AUTOSAR XML (schema 4-2-2)
package /KPIT/ARPackage
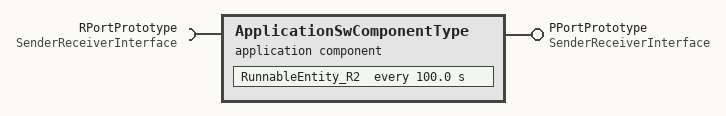
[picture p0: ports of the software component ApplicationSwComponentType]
  application sw component type ApplicationSwComponentType
    provide port PPortPrototype: provided-interface=SenderReceiverInterface
    require port RPortPrototype: required-interface=SenderReceiverInterface
    behavior SwcInternalBehavior_APSW_01: handle-termination-and-restart=NO-SUPPORT
      timing event TimingEvent_2: start-on-event=RunnableEntity_R2, period=100.0
      data received event DataReceivedEvent_APSW_01: start-on-event=RunnableEntity_R1
      35 x timing event:
        TimingEvent_1: start-on-event=RunnableEntity_R1, period=100.0
        TimingEvent_3: start-on-event=RunnableEntity_R3, period=200.0
        TimingEvent_4: start-on-event=RunnableEntity_R4, period=100.0
        TimingEvent_5: start-on-event=RunnableEntity_R5, period=100.0
        TimingEvent_18: start-on-event=RunnableEntity_R18, period=200.0
        TimingEvent_6: start-on-event=RunnableEntity_R6, period=200.0
        TimingEvent_7: start-on-event=RunnableEntity_R7, period=100.0
        TimingEvent_8: start-on-event=RunnableEntity_R8, period=100.0
        TimingEvent_9: start-on-event=RunnableEntity_R9, period=200.0
        TimingEvent_10: start-on-event=RunnableEntity_R10, period=100.0
        TimingEvent_11: start-on-event=RunnableEntity_R11, period=100.0
        TimingEvent_12: start-on-event=RunnableEntity_R12, period=200.0
        TimingEvent_13: start-on-event=RunnableEntity_R13, period=100.0
        TimingEvent_14: start-on-event=RunnableEntity_R14, period=100.0
        TimingEvent_15: start-on-event=RunnableEntity_R15, period=200.0
        TimingEvent_16: start-on-event=RunnableEntity_R16, period=100.0
        TimingEvent_17: start-on-event=RunnableEntity_R17, period=100.0
        TimingEvent_19: start-on-event=RunnableEntity_R1, period=100.0
        TimingEvent_20: start-on-event=RunnableEntity_R2, period=100.0
        TimingEvent_21: start-on-event=RunnableEntity_R3, period=200.0
        TimingEvent_22: start-on-event=RunnableEntity_R4, period=100.0
        TimingEvent_23: start-on-event=RunnableEntity_R5, period=100.0
        TimingEvent_24: start-on-event=RunnableEntity_R6, period=200.0
        TimingEvent_25: start-on-event=RunnableEntity_R7, period=100.0
        TimingEvent_26: start-on-event=RunnableEntity_R8, period=100.0
        TimingEvent_27: start-on-event=RunnableEntity_R9, period=200.0
        TimingEvent_28: start-on-event=RunnableEntity_R10, period=100.0
        TimingEvent_29: start-on-event=RunnableEntity_R11, period=100.0
        TimingEvent_30: start-on-event=RunnableEntity_R12, period=200.0
        TimingEvent_31: start-on-event=RunnableEntity_R13, period=100.0
        TimingEvent_32: start-on-event=RunnableEntity_R14, period=100.0
        TimingEvent_33: start-on-event=RunnableEntity_R15, period=200.0
        TimingEvent_34: start-on-event=RunnableEntity_R16, period=100.0
        TimingEvent_35: start-on-event=RunnableEntity_R17, period=100.0
        TimingEvent_36: start-on-event=RunnableEntity_R18, period=200.0
      36 x init event:
        InitEvent_I{1..18}: start-on-event=RunnableEntity_R{1..18}
        InitEvent_I19: start-on-event=RunnableEntity_R1
        InitEvent_I20: start-on-event=RunnableEntity_R2
        InitEvent_I21: start-on-event=RunnableEntity_R3
        InitEvent_I22: start-on-event=RunnableEntity_R4
        InitEvent_I23: start-on-event=RunnableEntity_R5
        InitEvent_I24: start-on-event=RunnableEntity_R6
        InitEvent_I25: start-on-event=RunnableEntity_R7
        InitEvent_I26: start-on-event=RunnableEntity_R8
        InitEvent_I27: start-on-event=RunnableEntity_R9
        InitEvent_I28: start-on-event=RunnableEntity_R10
        InitEvent_I29: start-on-event=RunnableEntity_R11
        InitEvent_I30: start-on-event=RunnableEntity_R12
        InitEvent_I31: start-on-event=RunnableEntity_R13
        InitEvent_I32: start-on-event=RunnableEntity_R14
        InitEvent_I33: start-on-event=RunnableEntity_R15
        InitEvent_I34: start-on-event=RunnableEntity_R16
        InitEvent_I35: start-on-event=RunnableEntity_R17
        InitEvent_I36: start-on-event=RunnableEntity_R18
      18 x runnable:
        RunnableEntity_R{1..14}
        RunnableEntity_R15: reentrancy-level=MULTICORE-REENTRANT
        RunnableEntity_R{16..18}
  sender receiver interface SenderReceiverInterface
    data VariableDataPrototype: type={Implementation_Data_type}
  module config Rte_0: definition=Rte, ecuc-def-edition=4.2.2, implementation-config-variant=VARIANT-PRE-COMPILE, module-description=Rte_Impl
    RteBswGeneral_0 (RteBswGeneral): RteSchMVersionInfoApi=true, RteUseComShadowSignalApi=false
    RteGeneration_0 (RteGeneration):
      RteBypassSupport = NONE
      RteCalibrationSupport = NONE
      RteCodeVendorId = 1
      RteDevErrorDetect = false
      RteDevErrorDetectUninit = false
      RteGenerationMode = COMPATIBILITY_MODE
      RteInExclusiveAreaCheckEnabled = true
      RteIocInteractionReturnValue = RTE_IOC
      RteMeasurementSupport = false
      RteOptimizationMode = RUNTIME
      RteValueRangeCheckEnabled = false
      RteVfbTraceEnabled = false
    RteInitializationBehavior_0 (RteInitializationBehavior): RteInitializationStrategy=RTE_INITIALIZATION_STRATEGY_AT_DATA_DECLARATION, RteSectionInitializationPolicy=1
    RteOsInteraction_0 (RteOsInteraction)
    72 x RteSwComponentInstance:
      RteSwComponentInstance_0
        RteEventToTaskMapping_0 (RteEventToTaskMapping):
          RteImmediateRestart = false
          RtePositionInTask = 1
          RteOsSchedulePoint = CONDITIONAL
          RteActivationOffset = 0
          RteEventRef = TimingEvent_1
          RteMappedToTaskRef = OsTask_0
          RteUsedOsAlarmRef = OsAlarm_0
          RteUsedOsEventRef = (unset)
      RteSwComponentInstance_1
        RteEventToTaskMapping_1 (RteEventToTaskMapping):
          RteImmediateRestart = false
          RteActivationOffset = 0
          RteOsSchedulePoint = CONDITIONAL
          RtePositionInTask = 2
          RteEventRef = TimingEvent_2
          RteMappedToTaskRef = OsTask_0
          RteUsedOsAlarmRef = OsAlarm_0
          RteUsedOsEventRef = (unset)
        RteInternalTriggerConfig_0 (RteInternalTriggerConfig): RteTriggerSourceQueueLength=0, RteSwcTriggerSourceRef=(unset)
      RteSwComponentInstance_2
        RteEventToTaskMapping_2 (RteEventToTaskMapping):
          RteImmediateRestart = false
          RteActivationOffset = 0
          RtePositionInTask = 3
          RteOsSchedulePoint = CONDITIONAL
          RteEventRef = TimingEvent_3
          RteMappedToTaskRef = OsTask_0
          RteUsedOsAlarmRef = OsAlarm_0
          RteUsedOsEventRef = (unset)
      RteSwComponentInstance_3
        RteEventToTaskMapping_3 (RteEventToTaskMapping):
          RteImmediateRestart = false
          RteActivationOffset = 0
          RteOsSchedulePoint = CONDITIONAL
          RtePositionInTask = 1
          RteEventRef = TimingEvent_4
          RteMappedToTaskRef = OsTask_1
          RteUsedOsAlarmRef = OsAlarm_1
          RteUsedOsEventRef = (unset)
      RteSwComponentInstance_4
        RteEventToTaskMapping_4 (RteEventToTaskMapping):
          RteImmediateRestart = false
          RteActivationOffset = 0
          RteOsSchedulePoint = CONDITIONAL
          RtePositionInTask = 2
          RteEventRef = TimingEvent_5
          RteUsedOsAlarmRef = OsAlarm_1
          RteUsedOsEventRef = (unset)
          RteMappedToTaskRef = OsTask_1
      RteSwComponentInstance_5
        RteEventToTaskMapping_5 (RteEventToTaskMapping):
          RteImmediateRestart = false
          RteActivationOffset = 0
          RtePositionInTask = 3
          RteOsSchedulePoint = CONDITIONAL
          RteEventRef = TimingEvent_6
          RteMappedToTaskRef = OsTask_1
          RteUsedOsAlarmRef = OsAlarm_1
      RteSwComponentInstance_6
        RteEventToTaskMapping_6 (RteEventToTaskMapping):
          RteImmediateRestart = false
          RteActivationOffset = 0
          RteOsSchedulePoint = CONDITIONAL
          RtePositionInTask = 1
          RteEventRef = TimingEvent_7
          RteUsedOsAlarmRef = OsAlarm_2
          RteMappedToTaskRef = OsTask_2
      RteSwComponentInstance_7
        RteEventToTaskMapping_7 (RteEventToTaskMapping):
          RteImmediateRestart = false
          RteActivationOffset = 0
          RteOsSchedulePoint = CONDITIONAL
          RtePositionInTask = 2
          RteEventRef = TimingEvent_8
          RteUsedOsAlarmRef = OsAlarm_2
          RteMappedToTaskRef = OsTask_2
      RteSwComponentInstance_8
        RteEventToTaskMapping_8 (RteEventToTaskMapping):
          RteImmediateRestart = false
          RteActivationOffset = 0
          RtePositionInTask = 3
          RteOsSchedulePoint = CONDITIONAL
          RteEventRef = TimingEvent_9
          RteUsedOsAlarmRef = OsAlarm_2
          RteMappedToTaskRef = OsTask_2
      RteSwComponentInstance_9
        RteEventToTaskMapping_9 (RteEventToTaskMapping):
          RteImmediateRestart = false
          RtePositionInTask = 1
          RteOsSchedulePoint = CONDITIONAL
          RteActivationOffset = 0
          RteEventRef = TimingEvent_10
          RteMappedToTaskRef = OsTask_3
          RteUsedOsAlarmRef = OsAlarm_3
      RteSwComponentInstance_10
        RteEventToTaskMapping_10 (RteEventToTaskMapping):
          RteImmediateRestart = false
          RteActivationOffset = 0
          RtePositionInTask = 2
          RteOsSchedulePoint = CONDITIONAL
          RteEventRef = TimingEvent_11
          RteMappedToTaskRef = OsTask_3
          RteUsedOsAlarmRef = OsAlarm_3
      RteSwComponentInstance_11
        RteEventToTaskMapping_11 (RteEventToTaskMapping):
          RteImmediateRestart = false
          RteActivationOffset = 0
          RtePositionInTask = 3
          RteOsSchedulePoint = CONDITIONAL
          RteEventRef = TimingEvent_12
          RteMappedToTaskRef = OsTask_3
          RteUsedOsAlarmRef = OsAlarm_3
      RteSwComponentInstance_12
        RteEventToTaskMapping_12 (RteEventToTaskMapping):
          RteImmediateRestart = false
          RteActivationOffset = 0
          RteOsSchedulePoint = CONDITIONAL
          RtePositionInTask = 1
          RteEventRef = TimingEvent_13
          RteMappedToTaskRef = OsTask_4
          RteUsedOsAlarmRef = OsAlarm_4
      RteSwComponentInstance_13
        RteEventToTaskMapping_13 (RteEventToTaskMapping):
          RteImmediateRestart = false
          RteOsSchedulePoint = CONDITIONAL
          RtePositionInTask = 2
          RteActivationOffset = 0
          RteEventRef = TimingEvent_14
          RteMappedToTaskRef = OsTask_4
          RteUsedOsAlarmRef = OsAlarm_4
      RteSwComponentInstance_14
        RteEventToTaskMapping_14 (RteEventToTaskMapping):
          RteImmediateRestart = false
          RteActivationOffset = 0
          RteOsSchedulePoint = CONDITIONAL
          RtePositionInTask = 3
          RteEventRef = TimingEvent_15
          RteMappedToTaskRef = OsTask_4
          RteUsedOsAlarmRef = OsAlarm_4
      RteSwComponentInstance_15
        RteEventToTaskMapping_15 (RteEventToTaskMapping):
          RteImmediateRestart = false
          RteActivationOffset = 0
          RtePositionInTask = 1
          RteOsSchedulePoint = CONDITIONAL
          RteEventRef = TimingEvent_16
          RteMappedToTaskRef = OsTask_5
          RteUsedOsAlarmRef = OsAlarm_5
      RteSwComponentInstance_16
        RteEventToTaskMapping_16 (RteEventToTaskMapping):
          RteImmediateRestart = false
          RteActivationOffset = 0
          RteOsSchedulePoint = CONDITIONAL
          RtePositionInTask = 2
          RteEventRef = TimingEvent_17
          RteMappedToTaskRef = OsTask_5
          RteUsedOsAlarmRef = OsAlarm_5
      RteSwComponentInstance_17
        RteEventToTaskMapping_17 (RteEventToTaskMapping):
          RteImmediateRestart = false
          RteActivationOffset = 0
          RtePositionInTask = 3
          RteOsSchedulePoint = CONDITIONAL
          RteEventRef = TimingEvent_18
          RteMappedToTaskRef = OsTask_5
          RteUsedOsAlarmRef = OsAlarm_5
      RteSwComponentInstance_18
        RteEventToTaskMapping_18 (RteEventToTaskMapping):
          RteImmediateRestart = false
          RteActivationOffset = 0
          RtePositionInTask = 1
          RteOsSchedulePoint = CONDITIONAL
          RteEventRef = TimingEvent_19
          RteMappedToTaskRef = OsTask_6
          RteUsedOsAlarmRef = OsAlarm_6
      RteSwComponentInstance_19
        RteEventToTaskMapping_19 (RteEventToTaskMapping):
          RteImmediateRestart = false
          RteActivationOffset = 0
          RtePositionInTask = 2
          RteOsSchedulePoint = CONDITIONAL
          RteEventRef = TimingEvent_20
          RteMappedToTaskRef = OsTask_6
          RteUsedOsAlarmRef = OsAlarm_6
      RteSwComponentInstance_20
        RteEventToTaskMapping_20 (RteEventToTaskMapping):
          RteImmediateRestart = false
          RteActivationOffset = 0
          RteOsSchedulePoint = CONDITIONAL
          RtePositionInTask = 3
          RteEventRef = TimingEvent_21
          RteMappedToTaskRef = OsTask_6
          RteUsedOsAlarmRef = OsAlarm_6
      RteSwComponentInstance_21
        RteEventToTaskMapping_21 (RteEventToTaskMapping):
          RteImmediateRestart = false
          RteActivationOffset = 0
          RtePositionInTask = 1
          RteOsSchedulePoint = CONDITIONAL
          RteEventRef = TimingEvent_22
          RteMappedToTaskRef = OsTask_7
          RteUsedOsAlarmRef = OsAlarm_7
      RteSwComponentInstance_22
        RteEventToTaskMapping_22 (RteEventToTaskMapping):
          RteImmediateRestart = false
          RteActivationOffset = 0
          RtePositionInTask = 2
          RteOsSchedulePoint = CONDITIONAL
          RteEventRef = TimingEvent_23
          RteMappedToTaskRef = OsTask_7
          RteUsedOsAlarmRef = OsAlarm_7
      RteSwComponentInstance_23
        RteEventToTaskMapping_23 (RteEventToTaskMapping):
          RteImmediateRestart = false
          RteActivationOffset = 0
          RtePositionInTask = 3
          RteOsSchedulePoint = CONDITIONAL
          RteEventRef = TimingEvent_24
          RteMappedToTaskRef = OsTask_7
          RteUsedOsAlarmRef = OsAlarm_7
      RteSwComponentInstance_24
        RteEventToTaskMapping_24 (RteEventToTaskMapping):
          RteImmediateRestart = false
          RteActivationOffset = 0
          RteOsSchedulePoint = CONDITIONAL
          RtePositionInTask = 1
          RteEventRef = TimingEvent_25
          RteMappedToTaskRef = OsTask_8
          RteUsedOsAlarmRef = OsAlarm_8
      RteSwComponentInstance_25
        RteEventToTaskMapping_25 (RteEventToTaskMapping):
          RteImmediateRestart = false
          RteActivationOffset = 0
          RteOsSchedulePoint = CONDITIONAL
          RtePositionInTask = 2
          RteEventRef = TimingEvent_26
          RteMappedToTaskRef = OsTask_8
          RteUsedOsAlarmRef = OsAlarm_8
      RteSwComponentInstance_26
        RteEventToTaskMapping_26 (RteEventToTaskMapping):
          RteImmediateRestart = false
          RteActivationOffset = 0
          RtePositionInTask = 3
          RteOsSchedulePoint = CONDITIONAL
          RteEventRef = TimingEvent_27
          RteMappedToTaskRef = OsTask_8
          RteUsedOsAlarmRef = OsAlarm_8
      RteSwComponentInstance_27
        RteEventToTaskMapping_27 (RteEventToTaskMapping):
          RteImmediateRestart = false
          RteActivationOffset = 0
          RteOsSchedulePoint = CONDITIONAL
          RtePositionInTask = 1
          RteEventRef = TimingEvent_28
          RteMappedToTaskRef = OsTask_9
          RteUsedOsAlarmRef = OsAlarm_9
      RteSwComponentInstance_28
        RteEventToTaskMapping_28 (RteEventToTaskMapping):
          RteImmediateRestart = false
          RteActivationOffset = 0
          RteOsSchedulePoint = CONDITIONAL
          RtePositionInTask = 2
          RteEventRef = TimingEvent_29
          RteMappedToTaskRef = OsTask_9
          RteUsedOsAlarmRef = OsAlarm_9
      RteSwComponentInstance_29
        RteEventToTaskMapping_29 (RteEventToTaskMapping):
          RteImmediateRestart = false
          RteActivationOffset = 0
          RteOsSchedulePoint = CONDITIONAL
          RtePositionInTask = 3
          RteEventRef = TimingEvent_30
          RteMappedToTaskRef = OsTask_9
          RteUsedOsAlarmRef = OsAlarm_9
      RteSwComponentInstance_30
        RteEventToTaskMapping_30 (RteEventToTaskMapping):
          RteImmediateRestart = false
          RteActivationOffset = 0
          RteOsSchedulePoint = CONDITIONAL
          RtePositionInTask = 1
          RteEventRef = TimingEvent_31
          RteMappedToTaskRef = OsTask_10
          RteUsedOsAlarmRef = OsAlarm_10
      RteSwComponentInstance_31
        RteEventToTaskMapping_31 (RteEventToTaskMapping):
          RteImmediateRestart = false
          RteActivationOffset = 0
          RteOsSchedulePoint = CONDITIONAL
          RtePositionInTask = 2
          RteEventRef = TimingEvent_32
          RteMappedToTaskRef = OsTask_10
          RteUsedOsAlarmRef = OsAlarm_10
      RteSwComponentInstance_32
        RteEventToTaskMapping_32 (RteEventToTaskMapping):
          RteImmediateRestart = false
          RteActivationOffset = 0
          RtePositionInTask = 3
          RteOsSchedulePoint = CONDITIONAL
          RteEventRef = TimingEvent_33
          RteMappedToTaskRef = OsTask_10
          RteUsedOsAlarmRef = OsAlarm_10
      RteSwComponentInstance_33
        RteEventToTaskMapping_33 (RteEventToTaskMapping):
          RteImmediateRestart = false
          RteActivationOffset = 0
          RteOsSchedulePoint = CONDITIONAL
          RtePositionInTask = 1
          RteEventRef = TimingEvent_34
          RteMappedToTaskRef = OsTask_11
          RteUsedOsAlarmRef = OsAlarm_11
      RteSwComponentInstance_34
        RteEventToTaskMapping_34 (RteEventToTaskMapping):
          RteImmediateRestart = false
          RteActivationOffset = 0
          RteOsSchedulePoint = CONDITIONAL
          RtePositionInTask = 2
          RteEventRef = TimingEvent_35
          RteMappedToTaskRef = OsTask_11
          RteUsedOsAlarmRef = OsAlarm_11
      RteSwComponentInstance_35
        RteEventToTaskMapping_35 (RteEventToTaskMapping):
          RteImmediateRestart = false
          RteActivationOffset = 0
          RteOsSchedulePoint = CONDITIONAL
          RtePositionInTask = 3
          RteEventRef = TimingEvent_36
          RteMappedToTaskRef = OsTask_11
          RteUsedOsAlarmRef = OsAlarm_11
      RteSwComponentInstance_36
        RteEventToTaskMapping_0 (RteEventToTaskMapping):
          RteImmediateRestart = false
          RtePositionInTask = 1
          RteOsSchedulePoint = CONDITIONAL
          RteActivationOffset = 0
          RteEventRef = InitEvent_I1
          RteMappedToTaskRef = OsTask_12
          RteUsedOsAlarmRef = (unset)
          RteUsedOsEventRef = (unset)
      RteSwComponentInstance_37
        RteEventToTaskMapping_1 (RteEventToTaskMapping):
          RteImmediateRestart = false
          RteActivationOffset = 0
          RteOsSchedulePoint = CONDITIONAL
          RtePositionInTask = 2
          RteEventRef = InitEvent_I2
          RteMappedToTaskRef = OsTask_12
          RteUsedOsAlarmRef = (unset)
          RteUsedOsEventRef = (unset)
        RteInternalTriggerConfig_0 (RteInternalTriggerConfig): RteTriggerSourceQueueLength=0, RteSwcTriggerSourceRef=(unset)
      RteSwComponentInstance_38
        RteEventToTaskMapping_2 (RteEventToTaskMapping):
          RteImmediateRestart = false
          RteActivationOffset = 0
          RtePositionInTask = 3
          RteOsSchedulePoint = CONDITIONAL
          RteEventRef = InitEvent_I3
          RteMappedToTaskRef = OsTask_12
          RteUsedOsAlarmRef = (unset)
          RteUsedOsEventRef = (unset)
      RteSwComponentInstance_39
        RteEventToTaskMapping_3 (RteEventToTaskMapping):
          RteImmediateRestart = false
          RteActivationOffset = 0
          RteOsSchedulePoint = CONDITIONAL
          RtePositionInTask = 1
          RteEventRef = InitEvent_I4
          RteMappedToTaskRef = OsTask_13
          RteUsedOsAlarmRef = (unset)
          RteUsedOsEventRef = (unset)
      RteSwComponentInstance_40
        RteEventToTaskMapping_4 (RteEventToTaskMapping):
          RteImmediateRestart = false
          RteActivationOffset = 0
          RteOsSchedulePoint = CONDITIONAL
          RtePositionInTask = 2
          RteEventRef = InitEvent_I5
          RteUsedOsAlarmRef = (unset)
          RteUsedOsEventRef = (unset)
          RteMappedToTaskRef = OsTask_13
      RteSwComponentInstance_41
        RteEventToTaskMapping_5 (RteEventToTaskMapping):
          RteImmediateRestart = false
          RteActivationOffset = 0
          RtePositionInTask = 3
          RteOsSchedulePoint = CONDITIONAL
          RteEventRef = InitEvent_I6
          RteMappedToTaskRef = OsTask_13
          RteUsedOsAlarmRef = (unset)
      RteSwComponentInstance_42
        RteEventToTaskMapping_6 (RteEventToTaskMapping):
          RteImmediateRestart = false
          RteActivationOffset = 0
          RteOsSchedulePoint = CONDITIONAL
          RtePositionInTask = 1
          RteEventRef = InitEvent_I7
          RteUsedOsAlarmRef = (unset)
          RteMappedToTaskRef = OsTask_14
      RteSwComponentInstance_43
        RteEventToTaskMapping_7 (RteEventToTaskMapping):
          RteImmediateRestart = false
          RteActivationOffset = 0
          RteOsSchedulePoint = CONDITIONAL
          RtePositionInTask = 2
          RteEventRef = InitEvent_I8
          RteUsedOsAlarmRef = (unset)
          RteMappedToTaskRef = OsTask_14
      RteSwComponentInstance_44
        RteEventToTaskMapping_8 (RteEventToTaskMapping):
          RteImmediateRestart = false
          RteActivationOffset = 0
          RtePositionInTask = 3
          RteOsSchedulePoint = CONDITIONAL
          RteEventRef = InitEvent_I9
          RteUsedOsAlarmRef = (unset)
          RteMappedToTaskRef = OsTask_14
      RteSwComponentInstance_45
        RteEventToTaskMapping_9 (RteEventToTaskMapping):
          RteImmediateRestart = false
          RtePositionInTask = 1
          RteOsSchedulePoint = CONDITIONAL
          RteActivationOffset = 0
          RteEventRef = InitEvent_I10
          RteMappedToTaskRef = OsTask_15
          RteUsedOsAlarmRef = (unset)
      RteSwComponentInstance_46
        RteEventToTaskMapping_10 (RteEventToTaskMapping):
          RteImmediateRestart = false
          RteActivationOffset = 0
          RtePositionInTask = 2
          RteOsSchedulePoint = CONDITIONAL
          RteEventRef = InitEvent_I11
          RteMappedToTaskRef = OsTask_15
          RteUsedOsAlarmRef = (unset)
      RteSwComponentInstance_47
        RteEventToTaskMapping_11 (RteEventToTaskMapping):
          RteImmediateRestart = false
          RteActivationOffset = 0
          RtePositionInTask = 3
          RteOsSchedulePoint = CONDITIONAL
          RteEventRef = InitEvent_I12
          RteMappedToTaskRef = OsTask_15
          RteUsedOsAlarmRef = (unset)
      RteSwComponentInstance_48
        RteEventToTaskMapping_12 (RteEventToTaskMapping):
          RteImmediateRestart = false
          RteActivationOffset = 0
          RteOsSchedulePoint = CONDITIONAL
          RtePositionInTask = 1
          RteEventRef = InitEvent_I13
          RteMappedToTaskRef = OsTask_16
          RteUsedOsAlarmRef = (unset)
      RteSwComponentInstance_49
        RteEventToTaskMapping_13 (RteEventToTaskMapping):
          RteImmediateRestart = false
          RteOsSchedulePoint = CONDITIONAL
          RtePositionInTask = 2
          RteActivationOffset = 0
          RteEventRef = InitEvent_I14
          RteMappedToTaskRef = OsTask_16
          RteUsedOsAlarmRef = (unset)
      RteSwComponentInstance_50
        RteEventToTaskMapping_14 (RteEventToTaskMapping):
          RteImmediateRestart = false
          RteActivationOffset = 0
          RteOsSchedulePoint = CONDITIONAL
          RtePositionInTask = 3
          RteEventRef = InitEvent_I15
          RteMappedToTaskRef = OsTask_16
          RteUsedOsAlarmRef = (unset)
      RteSwComponentInstance_51
        RteEventToTaskMapping_15 (RteEventToTaskMapping):
          RteImmediateRestart = false
          RteActivationOffset = 0
          RtePositionInTask = 1
          RteOsSchedulePoint = CONDITIONAL
          RteEventRef = InitEvent_I16
          RteMappedToTaskRef = OsTask_17
          RteUsedOsAlarmRef = (unset)
      RteSwComponentInstance_52
        RteEventToTaskMapping_16 (RteEventToTaskMapping):
          RteImmediateRestart = false
          RteActivationOffset = 0
          RteOsSchedulePoint = CONDITIONAL
          RtePositionInTask = 2
          RteEventRef = InitEvent_I17
          RteMappedToTaskRef = OsTask_17
          RteUsedOsAlarmRef = (unset)
      RteSwComponentInstance_53
        RteEventToTaskMapping_17 (RteEventToTaskMapping):
          RteImmediateRestart = false
          RteActivationOffset = 0
          RtePositionInTask = 3
          RteOsSchedulePoint = CONDITIONAL
          RteEventRef = InitEvent_I18
          RteMappedToTaskRef = OsTask_17
          RteUsedOsAlarmRef = (unset)
      RteSwComponentInstance_54
        RteEventToTaskMapping_18 (RteEventToTaskMapping):
          RteImmediateRestart = false
          RteActivationOffset = 0
          RtePositionInTask = 1
          RteOsSchedulePoint = CONDITIONAL
          RteEventRef = InitEvent_I19
          RteMappedToTaskRef = OsTask_18
          RteUsedOsAlarmRef = (unset)
      RteSwComponentInstance_55
        RteEventToTaskMapping_19 (RteEventToTaskMapping):
          RteImmediateRestart = false
          RteActivationOffset = 0
          RtePositionInTask = 2
          RteOsSchedulePoint = CONDITIONAL
          RteEventRef = InitEvent_I20
          RteMappedToTaskRef = OsTask_18
          RteUsedOsAlarmRef = (unset)
      RteSwComponentInstance_56
        RteEventToTaskMapping_20 (RteEventToTaskMapping):
          RteImmediateRestart = false
          RteActivationOffset = 0
          RteOsSchedulePoint = CONDITIONAL
          RtePositionInTask = 3
          RteEventRef = InitEvent_I21
          RteMappedToTaskRef = OsTask_18
          RteUsedOsAlarmRef = (unset)
      RteSwComponentInstance_57
        RteEventToTaskMapping_21 (RteEventToTaskMapping):
          RteImmediateRestart = false
          RteActivationOffset = 0
          RtePositionInTask = 1
          RteOsSchedulePoint = CONDITIONAL
          RteEventRef = InitEvent_I22
          RteMappedToTaskRef = OsTask_19
          RteUsedOsAlarmRef = (unset)
      RteSwComponentInstance_58
        RteEventToTaskMapping_22 (RteEventToTaskMapping):
          RteImmediateRestart = false
          RteActivationOffset = 0
          RtePositionInTask = 2
          RteOsSchedulePoint = CONDITIONAL
          RteEventRef = InitEvent_I23
          RteMappedToTaskRef = OsTask_19
          RteUsedOsAlarmRef = (unset)
      RteSwComponentInstance_59
        RteEventToTaskMapping_23 (RteEventToTaskMapping):
          RteImmediateRestart = false
          RteActivationOffset = 0
          RtePositionInTask = 3
          RteOsSchedulePoint = CONDITIONAL
          RteEventRef = InitEvent_I24
          RteMappedToTaskRef = OsTask_19
          RteUsedOsAlarmRef = (unset)
        RteExclusiveAreaImplementation_0 (RteExclusiveAreaImplementation): RteExclusiveAreaImplMechanism=, RteExclusiveAreaRef=(unset)
      RteSwComponentInstance_60
        RteEventToTaskMapping_24 (RteEventToTaskMapping):
          RteImmediateRestart = false
          RteActivationOffset = 0
          RteOsSchedulePoint = CONDITIONAL
          RtePositionInTask = 1
          RteEventRef = InitEvent_I25
          RteMappedToTaskRef = OsTask_20
          RteUsedOsAlarmRef = (unset)
      RteSwComponentInstance_61
        RteEventToTaskMapping_25 (RteEventToTaskMapping):
          RteImmediateRestart = false
          RteActivationOffset = 0
          RteOsSchedulePoint = CONDITIONAL
          RtePositionInTask = 2
          RteEventRef = InitEvent_I26
          RteMappedToTaskRef = OsTask_20
          RteUsedOsAlarmRef = (unset)
      RteSwComponentInstance_62
        RteEventToTaskMapping_26 (RteEventToTaskMapping):
          RteImmediateRestart = false
          RteActivationOffset = 0
          RtePositionInTask = 3
          RteOsSchedulePoint = CONDITIONAL
          RteEventRef = InitEvent_I27
          RteMappedToTaskRef = OsTask_20
          RteUsedOsAlarmRef = (unset)
      RteSwComponentInstance_63
        RteEventToTaskMapping_27 (RteEventToTaskMapping):
          RteImmediateRestart = false
          RteActivationOffset = 0
          RteOsSchedulePoint = CONDITIONAL
          RtePositionInTask = 1
          RteEventRef = InitEvent_I28
          RteMappedToTaskRef = OsTask_21
          RteUsedOsAlarmRef = (unset)
      RteSwComponentInstance_64
        RteEventToTaskMapping_28 (RteEventToTaskMapping):
          RteImmediateRestart = false
          RteActivationOffset = 0
          RteOsSchedulePoint = CONDITIONAL
          RtePositionInTask = 2
          RteEventRef = InitEvent_I29
          RteMappedToTaskRef = OsTask_21
          RteUsedOsAlarmRef = (unset)
      RteSwComponentInstance_65
        RteEventToTaskMapping_29 (RteEventToTaskMapping):
          RteImmediateRestart = false
          RteActivationOffset = 0
          RteOsSchedulePoint = CONDITIONAL
          RtePositionInTask = 3
          RteEventRef = InitEvent_I30
          RteMappedToTaskRef = OsTask_21
          RteUsedOsAlarmRef = (unset)
      RteSwComponentInstance_66
        RteEventToTaskMapping_30 (RteEventToTaskMapping):
          RteImmediateRestart = false
          RteActivationOffset = 0
          RteOsSchedulePoint = CONDITIONAL
          RtePositionInTask = 1
          RteEventRef = InitEvent_I31
          RteMappedToTaskRef = OsTask_22
          RteUsedOsAlarmRef = (unset)
      RteSwComponentInstance_67
        RteEventToTaskMapping_31 (RteEventToTaskMapping):
          RteImmediateRestart = false
          RteActivationOffset = 0
          RteOsSchedulePoint = CONDITIONAL
          RtePositionInTask = 2
          RteEventRef = InitEvent_I32
          RteMappedToTaskRef = OsTask_22
          RteUsedOsAlarmRef = (unset)
      RteSwComponentInstance_68
        RteEventToTaskMapping_32 (RteEventToTaskMapping):
          RteImmediateRestart = false
          RteActivationOffset = 0
          RtePositionInTask = 3
          RteOsSchedulePoint = CONDITIONAL
          RteEventRef = InitEvent_I33
          RteMappedToTaskRef = OsTask_22
          RteUsedOsAlarmRef = (unset)
      RteSwComponentInstance_69
        RteEventToTaskMapping_33 (RteEventToTaskMapping):
          RteImmediateRestart = false
          RteActivationOffset = 0
          RteOsSchedulePoint = CONDITIONAL
          RtePositionInTask = 1
          RteEventRef = InitEvent_I34
          RteMappedToTaskRef = OsTask_23
          RteUsedOsAlarmRef = (unset)
      RteSwComponentInstance_70
        RteEventToTaskMapping_34 (RteEventToTaskMapping):
          RteImmediateRestart = false
          RteActivationOffset = 0
          RteOsSchedulePoint = CONDITIONAL
          RtePositionInTask = 2
          RteEventRef = InitEvent_I35
          RteMappedToTaskRef = OsTask_23
          RteUsedOsAlarmRef = (unset)
      RteSwComponentInstance_71
        RteEventToTaskMapping_35 (RteEventToTaskMapping):
          RteImmediateRestart = false
          RteActivationOffset = 0
          RteOsSchedulePoint = CONDITIONAL
          RtePositionInTask = 3
          RteEventRef = InitEvent_I36
          RteMappedToTaskRef = OsTask_23
          RteUsedOsAlarmRef = (unset)
  module config Os_0: definition=Os, ecuc-def-edition=1.1.0, implementation-config-variant=VARIANT-PRE-COMPILE, module-description=BswImplementation_Os
    OsAppMode_1 (OsAppMode)
    OsOS_0 (OsOS):
      OsIdleTaskStackSize = 600
      OsProcessor = MPC5748G
      OsStackMonitoring = false
      OsStatus = STANDARD
      OsUseGetServiceId = false
      OsUseParameterAccess = false
      OsUseResScheduler = true
      OsHooks_0 (OsHooks): OsErrorHook=false, OsPostTaskHook=false, OsPreTaskHook=false, OsShutdownHook=false, OsStartupHook=false
    6 x OsTask, all with OsTaskStackSize=800:
      OsTask_0: OsTaskActivation=2, OsTaskPriority=1, OsTaskSchedule=FULL
        OsTaskTimingProtection_0 (OsTaskTimingProtection)
        OsTaskAutostart_0 (OsTaskAutostart): OsTaskAppModeRef=OsAppMode_1
      OsTask_1: OsTaskActivation=1, OsTaskPriority=2, OsTaskSchedule=NON
        OsTaskAutostart_0 (OsTaskAutostart): OsTaskAppModeRef=OsAppMode_1
      OsTask_2: OsTaskActivation=1, OsTaskPriority=3, OsTaskSchedule=FULL
        OsTaskAutostart_0 (OsTaskAutostart): OsTaskAppModeRef=OsAppMode_1
        OsTaskTimingProtection_0 (OsTaskTimingProtection)
      OsTask_3: OsTaskActivation=2, OsTaskPriority=4, OsTaskSchedule=NON
        OsTaskTimingProtection_0 (OsTaskTimingProtection): OsTaskTimeFrame=0.0000002
      OsTask_4: OsTaskActivation=1, OsTaskPriority=5, OsTaskSchedule=FULL
        OsTaskTimingProtection_0 (OsTaskTimingProtection)
      OsTask_5: OsTaskActivation=2, OsTaskPriority=6, OsTaskSchedule=FULL
        OsTaskTimingProtection_0 (OsTaskTimingProtection): OsTaskTimeFrame=0.0000005
    4 x OsAlarm:
      OsAlarm_1: OsAlarmCounterRef=OsCounter_1
        OsAlarmAction_1 (OsAlarmAction)
          OsAlarmActivateTask_1 (OsAlarmActivateTask): OsAlarmActivateTaskRef=OsTask_1
        OsAlarmAutostart_1 (OsAlarmAutostart): OsAlarmAlarmTime=1, OsAlarmAutostartType=RELATIVE, OsAlarmCycleTime=0, OsAlarmAppModeRef=OsAppMode_1
      OsAlarm_2: OsAlarmCounterRef=OsCounter_0
        OsAlarmAction_2 (OsAlarmAction)
          OsAlarmActivateTask_2 (OsAlarmActivateTask): OsAlarmActivateTaskRef=OsTask_2
        OsAlarmAutostart_2 (OsAlarmAutostart): OsAlarmAlarmTime=1, OsAlarmAutostartType=RELATIVE, OsAlarmCycleTime=0, OsAlarmAppModeRef=OsAppMode_1
      OsAlarm_3: OsAlarmCounterRef=OsCounter_1
        OsAlarmAction_3 (OsAlarmAction)
          OsAlarmActivateTask_3 (OsAlarmActivateTask): OsAlarmActivateTaskRef=OsTask_3
        OsAlarmAutostart_0 (OsAlarmAutostart): OsAlarmAlarmTime=1, OsAlarmAutostartType=RELATIVE, OsAlarmCycleTime=0, OsAlarmAppModeRef=OsAppMode_1
      OsAlarm_4: OsAlarmCounterRef=OsCounter_0
        OsAlarmAction_4 (OsAlarmAction)
          OsAlarmActivateTask_4 (OsAlarmActivateTask): OsAlarmActivateTaskRef=OsTask_4
        OsAlarmAutostart_0 (OsAlarmAutostart): OsAlarmAlarmTime=1, OsAlarmAutostartType=RELATIVE, OsAlarmCycleTime=0, OsAlarmAppModeRef=OsAppMode_1
    4 x OsCounter, all with OsCounterMaxAllowedValue=1, OsCounterMinCycle=1, OsCounterTicksPerBase=1, OsCounterType=HARDWARE, OsSecondsPerTick=0.0000002:
      OsCounter_0: OsDrivingInterrupt=
        OsDriver_0 (OsDriver)
      OsCounter_1
      OsCounter_2
        OsTimeConstant_0 (OsTimeConstant): OsTimeValue=0, OsConstName=(unset)
      OsCounter_3
    OsAlarm_0 (OsAlarm): OsAlarmCounterRef=OsCounter_0
      OsAlarmAction_0 (OsAlarmAction)
        OsAlarmActivateTask_0 (OsAlarmActivateTask): OsAlarmActivateTaskRef=OsTask_0
      OsAlarmAutostart_0 (OsAlarmAutostart): OsAlarmAlarmTime=1, OsAlarmAutostartType=RELATIVE, OsAlarmCycleTime=0, OsAlarmAppModeRef=OsAppMode_1
    OsApplication_0 (OsApplication):
      OsTrusted = false
      OsTrustedApplicationDelayTimingViolationCall = true
      OsTrustedApplicationWithProtection = false
      OsPeripheralAcess = 
      OsAppAlarmRef = OsAlarm_0
      OsAppCounterRef = OsCounter_0
      OsAppTaskRef = OsTask_0
      OsApplicationCoreRef = EcucCoreDefinition_0
      OsAppEcucPartitionRef = Partition0
      OsAppAlarmRef = OsAlarm_{1..5}
      OsAppCounterRef = OsCounter_1
      OsAppIsrRef = OsIsr_0
      OsAppIsrRef = OsIsr_1
      OsAppTaskRef = OsTask_{1..5}
      OsAppIsrRef = OsIsr_{2..4}
      OsAppTaskRef = OsTask_{12..17}
      OsApplicationHooks_0 (OsApplicationHooks): OsAppErrorHook=false, OsAppShutdownHook=false, OsAppStartupHook=false
    OsApplication_1 (OsApplication):
      OsTrusted = false
      OsTrustedApplicationDelayTimingViolationCall = true
      OsTrustedApplicationWithProtection = false
      OsAppAlarmRef = OsAlarm_6
      OsAppCounterRef = OsCounter_2
      OsAppTaskRef = OsTask_6
      OsApplicationCoreRef = EcucCoreDefinition_1
      OsAppEcucPartitionRef = Partition1
      OsAppAlarmRef = OsAlarm_{7..11}
      OsAppCounterRef = OsCounter_3
      OsAppIsrRef = OsIsr_5
      OsAppIsrRef = OsIsr_6
      OsAppTaskRef = OsTask_{7..11}
      OsAppIsrRef = OsIsr_{7..9}
      OsAppTaskRef = OsTask_{18..23}
      OsApplicationHooks_0 (OsApplicationHooks): OsAppErrorHook=false, OsAppShutdownHook=false, OsAppStartupHook=false
      OsApplicationTrustedFunction_0 (OsApplicationTrustedFunction): OsTrustedFunctionName=(unset)
    6 x OsTask, all with OsTaskActivation=1, OsTaskSchedule=FULL, OsTaskStackSize=800:
      OsTask_6: OsTaskPriority=7
      OsTask_7: OsTaskPriority=8
      OsTask_8: OsTaskPriority=9
      OsTask_9: OsTaskPriority=10
      OsTask_10: OsTaskPriority=11
      OsTask_11: OsTaskPriority=12
        OsTaskTimingProtection_0 (OsTaskTimingProtection): OsTaskTimeFrame=0.0000005
    4 x OsIsr, all with OsIsrName=, OsIsrStackSize=4:
      OsIsr_0: OsIsrCategory=CATEGORY_2, OsIsrHardwarePriority=1, OsIsrResourceRef=(unset)
      OsIsr_1: OsIsrCategory=CATEGORY_2, OsIsrHardwarePriority=2
      OsIsr_2: OsIsrCategory=CATEGORY_2, OsIsrHardwarePriority=3
        OsIsrTimingProtection_0 (OsIsrTimingProtection): OsIsrTimeFrame=0.0000001
      OsIsr_3: OsIsrCategory=CATEGORY_1, OsIsrHardwarePriority=4
    7 x OsAlarm:
      OsAlarm_5: OsAlarmCounterRef=OsCounter_1
        OsAlarmAction_0 (OsAlarmAction)
          OsAlarmActivateTask_0 (OsAlarmActivateTask): OsAlarmActivateTaskRef=OsTask_5
        OsAlarmAutostart_0 (OsAlarmAutostart): OsAlarmAlarmTime=1, OsAlarmAutostartType=RELATIVE, OsAlarmCycleTime=0, OsAlarmAppModeRef=OsAppMode_1
      OsAlarm_6: OsAlarmCounterRef=OsCounter_2
        OsAlarmAction_0 (OsAlarmAction)
          OsAlarmActivateTask_0 (OsAlarmActivateTask): OsAlarmActivateTaskRef=OsTask_6
        OsAlarmAutostart_0 (OsAlarmAutostart): OsAlarmAlarmTime=1, OsAlarmAutostartType=RELATIVE, OsAlarmCycleTime=0, OsAlarmAppModeRef=OsAppMode_1
      OsAlarm_7: OsAlarmCounterRef=OsCounter_3
        OsAlarmAction_0 (OsAlarmAction)
          OsAlarmActivateTask_0 (OsAlarmActivateTask): OsAlarmActivateTaskRef=OsTask_7
        OsAlarmAutostart_0 (OsAlarmAutostart): OsAlarmAlarmTime=1, OsAlarmAutostartType=RELATIVE, OsAlarmCycleTime=0, OsAlarmAppModeRef=OsAppMode_1
      OsAlarm_8: OsAlarmCounterRef=OsCounter_2
        OsAlarmAction_0 (OsAlarmAction)
          OsAlarmActivateTask_0 (OsAlarmActivateTask): OsAlarmActivateTaskRef=OsTask_8
        OsAlarmAutostart_0 (OsAlarmAutostart): OsAlarmAlarmTime=1, OsAlarmAutostartType=RELATIVE, OsAlarmCycleTime=0, OsAlarmAppModeRef=OsAppMode_1
      OsAlarm_9: OsAlarmCounterRef=OsCounter_3
        OsAlarmAction_0 (OsAlarmAction)
          OsAlarmActivateTask_0 (OsAlarmActivateTask): OsAlarmActivateTaskRef=OsTask_9
        OsAlarmAutostart_0 (OsAlarmAutostart): OsAlarmAlarmTime=1, OsAlarmAutostartType=RELATIVE, OsAlarmCycleTime=0, OsAlarmAppModeRef=OsAppMode_1
      OsAlarm_10: OsAlarmCounterRef=OsCounter_2
        OsAlarmAction_0 (OsAlarmAction)
          OsAlarmActivateTask_0 (OsAlarmActivateTask): OsAlarmActivateTaskRef=OsTask_10
        OsAlarmAutostart_0 (OsAlarmAutostart): OsAlarmAlarmTime=1, OsAlarmAutostartType=RELATIVE, OsAlarmCycleTime=0, OsAlarmAppModeRef=OsAppMode_1
      OsAlarm_11: OsAlarmCounterRef=OsCounter_3
        OsAlarmAction_0 (OsAlarmAction)
          OsAlarmActivateTask_0 (OsAlarmActivateTask): OsAlarmActivateTaskRef=OsTask_11
        OsAlarmAutostart_0 (OsAlarmAutostart): OsAlarmAlarmTime=1, OsAlarmAutostartType=RELATIVE, OsAlarmCycleTime=0, OsAlarmAppModeRef=OsAppMode_1
    6 x OsIsr, all with OsIsrName=, OsIsrStackSize=4:
      OsIsr_4: OsIsrCategory=CATEGORY_1, OsIsrHardwarePriority=5
        OsIsrTimingProtection_0 (OsIsrTimingProtection): OsIsrTimeFrame=0.0000001
      OsIsr_5: OsIsrCategory=CATEGORY_2, OsIsrHardwarePriority=6
      OsIsr_6: OsIsrCategory=CATEGORY_2, OsIsrHardwarePriority=7
        OsIsrTimingProtection_0 (OsIsrTimingProtection): OsIsrTimeFrame=0.0000001
      OsIsr_7: OsIsrCategory=CATEGORY_2, OsIsrHardwarePriority=8
      OsIsr_8: OsIsrCategory=CATEGORY_1, OsIsrHardwarePriority=9
        OsIsrTimingProtection_0 (OsIsrTimingProtection): OsIsrTimeFrame=0.0000001
      OsIsr_9: OsIsrCategory=CATEGORY_1, OsIsrHardwarePriority=10
    12 x OsTask, all with OsTaskActivation=1, OsTaskSchedule=FULL, OsTaskStackSize=800:
      OsTask_12: OsTaskPriority=13
        OsTaskAutostart_0 (OsTaskAutostart): OsTaskAppModeRef=OsAppMode_1
      OsTask_13: OsTaskPriority=14
        OsTaskAutostart_0 (OsTaskAutostart): OsTaskAppModeRef=OsAppMode_1
      OsTask_14: OsTaskPriority=15
        OsTaskAutostart_0 (OsTaskAutostart): OsTaskAppModeRef=OsAppMode_1
      OsTask_15: OsTaskPriority=16
        OsTaskAutostart_0 (OsTaskAutostart): OsTaskAppModeRef=OsAppMode_1
      OsTask_16: OsTaskPriority=17
      OsTask_17: OsTaskPriority=18
      OsTask_18: OsTaskPriority=19
        OsTaskAutostart_0 (OsTaskAutostart): OsTaskAppModeRef=OsAppMode_1
      OsTask_19: OsTaskPriority=20
        OsTaskAutostart_0 (OsTaskAutostart): OsTaskAppModeRef=OsAppMode_1
      OsTask_20: OsTaskPriority=21
        OsTaskAutostart_0 (OsTaskAutostart): OsTaskAppModeRef=OsAppMode_1
      OsTask_21: OsTaskPriority=22
      OsTask_22: OsTaskPriority=23
      OsTask_23: OsTaskPriority=24
package /KPIT/ActiveEcuC
  ecuc value collection ActiveEcuC: ecu-extract=M3_System, ecuc-values=[WdgM_0, EcuC_0, Fls, Mcu]
  module config EcuC_0: definition=EcuC, ecuc-def-edition=4.2.2, implementation-config-variant=VARIANT-PRE-COMPILE
    EcucConfigSet_0 (EcucConfigSet): EcucSafeKSAR=false
      EcucPduCollection_0 (EcucPduCollection): PduIdTypeEnum=UINT8, PduLengthTypeEnum=UINT8
        53 x Pdu, all with MetaDataLength=0:
          Pdu_ISignalIPdu_CMM_1A8_CAN00: PduLength=8, SysTPduToPduTriggeringRef=PduTriggering_CMM_1A8
          Pdu_ISignalIPdu_CRASH_4C8_CAN00: PduLength=3, SysTPduToPduTriggeringRef=PduTriggering_CRASH_4C8
          Pdu_ISignalIPdu_DAT_E_VCU_398_CAN00: PduLength=4, SysTPduToPduTriggeringRef=PduTriggering_DAT_E_VCU_398
          Pdu_ISignalIPdu_DAT_E_VCU_4D1_CAN00: PduLength=6, SysTPduToPduTriggeringRef=PduTriggering_DAT_E_VCU_4D1
          Pdu_ISignalIPdu_DAT_E_VCU_4F1_CAN00: PduLength=8, SysTPduToPduTriggeringRef=PduTriggering_DAT_E_VCU_4F1
          Pdu_ISignalIPdu_DAT_MCU_586_CAN00: PduLength=6, SysTPduToPduTriggeringRef=PduTriggering_DAT_MCU_586
          Pdu_ISignalIPdu_DAT_OBC_DCDC_531_CAN00: PduLength=4, SysTPduToPduTriggeringRef=PduTriggering_DAT_OBC_DCDC_531
          Pdu_ISignalIPdu_DYN_ESC_0ED_CAN00: PduLength=4, SysTPduToPduTriggeringRef=PduTriggering_DYN_ESC_0ED
          Pdu_ISignalIPdu_DYN_ESC_12D_CAN00: PduLength=6, SysTPduToPduTriggeringRef=PduTriggering_DYN_ESC_12D
          Pdu_ISignalIPdu_DYN_E_VCU_342_CAN00: PduLength=8, SysTPduToPduTriggeringRef=PduTriggering_DYN_E_VCU_342
          Pdu_ISignalIPdu_DYN_E_VCU_428_CAN00: PduLength=8, SysTPduToPduTriggeringRef=PduTriggering_DYN_E_VCU_428
          Pdu_ISignalIPdu_DYN_MCU_046_CAN00: PduLength=4, SysTPduToPduTriggeringRef=PduTriggering_DYN_MCU_046
          Pdu_ISignalIPdu_DYN_MCU_066_CAN00: PduLength=4, SysTPduToPduTriggeringRef=PduTriggering_DYN_MCU_066
          Pdu_ISignalIPdu_DYN_MCU_2C6_CAN00: PduLength=7, SysTPduToPduTriggeringRef=PduTriggering_DYN_MCU_2C6
          Pdu_ISignalIPdu_ELECTRON_BSI_092_CAN00: PduLength=1, SysTPduToPduTriggeringRef=PduTriggering_ELECTRON_BSI_092
          Pdu_ISignalIPdu_E_VCU_1B8_CAN00: PduLength=8, SysTPduToPduTriggeringRef=PduTriggering_E_VCU_1B8
          Pdu_ISignalIPdu_E_VCU_1D8_CAN00: PduLength=8, SysTPduToPduTriggeringRef=PduTriggering_E_VCU_1D8
          Pdu_ISignalIPdu_E_VCU_238_CAN00: PduLength=8, SysTPduToPduTriggeringRef=PduTriggering_E_VCU_238
          Pdu_ISignalIPdu_IMMO_MCU_VSM_0C6_CAN00: PduLength=8, SysTPduToPduTriggeringRef=PduTriggering_IMMO_MCU_VSM_0C6
          Pdu_ISignalIPdu_IMMO_MCU_VSM_0E6_CAN00: PduLength=8, SysTPduToPduTriggeringRef=PduTriggering_IMMO_MCU_VSM_0E6
          Pdu_ISignalIPdu_IMMO_VSM_MCU_04D_CAN00: PduLength=8, SysTPduToPduTriggeringRef=PduTriggering_IMMO_VSM_MCU_04D
          Pdu_ISignalIPdu_IMMO_VSM_MCU_06D_CAN00: PduLength=8, SysTPduToPduTriggeringRef=PduTriggering_IMMO_VSM_MCU_06D
          Pdu_ISignalIPdu_MCU1_112_CAN00: PduLength=8, SysTPduToPduTriggeringRef=PduTriggering_MCU1_112
          Pdu_ISignalIPdu_MCU_146_CAN00: PduLength=8, SysTPduToPduTriggeringRef=PduTriggering_MCU_146
          Pdu_ISignalIPdu_MCU_186_CAN00: PduLength=8, SysTPduToPduTriggeringRef=PduTriggering_MCU_186
          Pdu_ISignalIPdu_MCU_526_CAN00: PduLength=4, SysTPduToPduTriggeringRef=PduTriggering_MCU_526
          Pdu_ISignalIPdu_MCU_5C6_CAN00: PduLength=3, SysTPduToPduTriggeringRef=PduTriggering_MCU_5C6
          Pdu_ISignalIPdu_NEW_JDD_55F_CAN00: PduLength=1, SysTPduToPduTriggeringRef=PduTriggering_NEW_JDD_55F
          Pdu_ISignalIPdu_NEW_JDD_MCU_766_CAN00: PduLength=8, SysTPduToPduTriggeringRef=PduTriggering_NEW_JDD_MCU_766
          Pdu_ISignalIPdu_REP_DIAG_ON_CAN_686_CAN00: PduLength=8, SysTPduToPduTriggeringRef=PduTriggering_REP_DIAG_ON_CAN_686
          Pdu_ISignalIPdu_REQ_DIAG_ON_CAN_6A6_CAN00: PduLength=8, SysTPduToPduTriggeringRef=PduTriggering_REQ_DIAG_ON_CAN_6A6
          Pdu_ISignalIPdu_SUPV_V2_MCU_786_CAN00: PduLength=8, SysTPduToPduTriggeringRef=PduTriggering_SUPV_V2_MCU_786
          Pdu_ISignalIPdu_TBMU_4B4_CAN00: PduLength=4, SysTPduToPduTriggeringRef=PduTriggering_TBMU_4B4
          Pdu_ISignalIPdu_TBMU_V2_214_CAN00: PduLength=8, SysTPduToPduTriggeringRef=PduTriggering_TBMU_V2_214
          Pdu_ISignalIPdu_TBMU_V2_4F4_CAN00: PduLength=8, SysTPduToPduTriggeringRef=PduTriggering_TBMU_V2_4F4
          Pdu_ISignalIPdu_UDS_ON_CAN_7FF_CAN00: PduLength=8, SysTPduToPduTriggeringRef=PduTriggering_UDS_ON_CAN_7FF
          Pdu_ISignalIPdu_V2_BSI_552_CAN00: PduLength=8, SysTPduToPduTriggeringRef=PduTriggering_V2_BSI_552
          Pdu_ISignalIPdu_VCU_BSI_Wakeup_27A_CAN00: PduLength=8, SysTPduToPduTriggeringRef=PduTriggering_VCU_BSI_Wakeup_27A
          Pdu_ISignalIPdu_VCU_PCANInfo_17B_CAN00: PduLength=8, SysTPduToPduTriggeringRef=PduTriggering_VCU_PCANInfo_17B
          Pdu_ISignalIPdu_VERS_MCU_106_CAN00: PduLength=8, SysTPduToPduTriggeringRef=PduTriggering_VERS_MCU_106
          Pdu_Multiplexed_IMMO_BSI_MCU_0AE_CAN00_IPduPort_IMMO_BSI_MCU_0AE_MCU_Ext_noKeyCtlUnit_IN: PduLength=5, SysTPduToPduTriggeringRef=PduTriggering_Multiplexed_IMMO_BSI_MCU_0AE_CAN00_IMMO_BSI_MCU_0AE_BSI
          Pdu_Multiplexed_IMMO_BSI_MCU_0AE_CAN00_IPduPort_IMMO_BSI_MCU_0AE_MCU_Ext_BsiMcuImmoLid_IN: PduLength=5, SysTPduToPduTriggeringRef=PduTriggering_Multiplexed_IMMO_BSI_MCU_0AE_CAN00_IMMO_BSI_MCU_0AE_BSI
          Pdu_Multiplexed_IMMO_MCU_BSI_0A6_CAN00: PduLength=5, SysTPduToPduTriggeringRef=PduTriggering_Multiplexed_IMMO_MCU_BSI_0A6_CAN00_IMMO_MCU_BSI_0A6_MCU
          Pdu_ISignalIPdu_Priv_RX_XCP_686: PduLength=8, SysTPduToPduTriggeringRef=(unset)
          Pdu_ISignalIPdu_Priv_TX_XCP_7CC: PduLength=8, SysTPduToPduTriggeringRef=(unset)
          Pdu_ISignalIPdu_Priv_TX_XCP_7CD: PduLength=8, SysTPduToPduTriggeringRef=(unset)
          Pdu_ISignalIPdu_Priv_TX_XCP_7CE: PduLength=8, SysTPduToPduTriggeringRef=(unset)
          Pdu_ISignalIPdu_Priv_TX_XCP_7CF: PduLength=8, SysTPduToPduTriggeringRef=(unset)
          Pdu_ISignalIPdu_RX_XCP_686: PduLength=8, SysTPduToPduTriggeringRef=(unset)
          Pdu_ISignalIPdu_TX_XCP_7CC: PduLength=8, SysTPduToPduTriggeringRef=(unset)
          Pdu_ISignalIPdu_TX_XCP_7CD: PduLength=8, SysTPduToPduTriggeringRef=(unset)
          Pdu_ISignalIPdu_TX_XCP_7CE: PduLength=8, SysTPduToPduTriggeringRef=(unset)
          Pdu_ISignalIPdu_TX_XCP_7CF: PduLength=8, SysTPduToPduTriggeringRef=(unset)
    EcucHardware_0 (EcucHardware)
      EcucCoreDefinition_0 (EcucCoreDefinition): EcucCoreId=0
      EcucCoreDefinition_1 (EcucCoreDefinition): EcucCoreId=1
    EcucPartitionCollection
      Partition1 (EcucPartition):
        index = 0
        EcucPartitionBswModuleExecution = true
        EcucPartitionQmBswModuleExecution = true
        PartitionCanBeRestarted = false
        EcucPartitionSoftwareComponentInstanceRef = WdgM
        EcucPartitionSoftwareComponentInstanceRef = WdgM_App
        EcucPartitionBswModuleDistinguishedPartition = BDP_BswM_Config_0
        EcucPartitionSoftwareComponentInstanceRef = ASW_WdgM
      Partition0 (EcucPartition):
        index = 3
        EcucPartitionBswModuleExecution = false
        EcucPartitionQmBswModuleExecution = true
        PartitionCanBeRestarted = true
        EcucPartitionSoftwareComponentInstanceRef = WdgM_App_Core0ASILB
        EcucPartitionSoftwareComponentInstanceRef = WdgM_MasterPartition2
  module config WdgM_0: definition=WdgM, ecuc-def-edition=4.6.0, implementation-config-variant=VARIANT-PRE-COMPILE, module-description=BswImplmentation_WdgM
    WdgMConfigSet_0 (WdgMConfigSet): WdgMInitialMode=WdgMMode_1
      WdgMMode_0 (WdgMMode): WdgMModeId=0, WdgMSupervisionCycle=0.010, WdgMExpiredSupervisionCycleTol=0
        WdgMTrigger_0 (WdgMTrigger): WdgMWatchdogMode=WDGIF_SLOW_MODE, WdgMTriggerConditionValue=500, WdgMTriggerWatchdogRef=WdgMWatchdog_0
        21 x WdgMAliveSupervision, all with WdgMMinMargin=1, WdgMMaxMargin=1:
          WdgMAliveSupervision_Core0ASILA_100ms_Task: WdgMExpectedAliveIndications=2, WdgMSupervisionReferenceCycle=20, WdgMAliveSupervisionCheckpointRef=WdgMCore0ASILA_100msEndChkpnt
          WdgMAliveSupervision_Core0ASILA_10ms_Task: WdgMSupervisionReferenceCycle=10, WdgMExpectedAliveIndications=10, WdgMAliveSupervisionCheckpointRef=WdgMCore0ASILA_10msEndChkpnt
          WdgMAliveSupervision_Core0ASILA_1ms_Task: WdgMExpectedAliveIndications=10, WdgMSupervisionReferenceCycle=1, WdgMAliveSupervisionCheckpointRef=WdgMCore0ASILA_1msEndChkpnt
          WdgMAliveSupervision_Core0ASILA_40ms_Task: WdgMExpectedAliveIndications=3, WdgMSupervisionReferenceCycle=12, WdgMAliveSupervisionCheckpointRef=WdgMCore0ASILA_40msEndChkpnt
          WdgMAliveSupervision_Core0ASILA_5ms_Task: WdgMExpectedAliveIndications=10, WdgMSupervisionReferenceCycle=5, WdgMAliveSupervisionCheckpointRef=WdgMCore0ASILA_5msEndChkpnt
          WdgMAliveSupervision_Core0ASILB_100ms_Task: WdgMSupervisionReferenceCycle=20, WdgMExpectedAliveIndications=2, WdgMAliveSupervisionCheckpointRef=WdgMCore0ASILB_100msEndChkpnt
          WdgMAliveSupervision_Core0ASILB_10ms_Task: WdgMSupervisionReferenceCycle=10, WdgMExpectedAliveIndications=10, WdgMAliveSupervisionCheckpointRef=WdgMCore0ASILB_10msEndChkpnt
          WdgMAliveSupervision_Core0ASILB_1ms_Task: WdgMExpectedAliveIndications=10, WdgMSupervisionReferenceCycle=1, WdgMAliveSupervisionCheckpointRef=WdgMCore0ASILB_1msEndChkpnt
          WdgMAliveSupervision_Core0ASILB_40ms_Task: WdgMExpectedAliveIndications=3, WdgMSupervisionReferenceCycle=12, WdgMAliveSupervisionCheckpointRef=WdgMCore0ASILB_40msEndChkpnt
          WdgMAliveSupervision_Core0ASILB_5ms_Task: WdgMSupervisionReferenceCycle=5, WdgMExpectedAliveIndications=10, WdgMAliveSupervisionCheckpointRef=WdgMCore0ASILB_5msEndChkpnt
          WdgMAliveSupervision_Core0ASILC_100ms_Task: WdgMSupervisionReferenceCycle=20, WdgMExpectedAliveIndications=2, WdgMAliveSupervisionCheckpointRef=WdgMCore0ASILC_100msEndChkpnt
          WdgMAliveSupervision_Core0ASILC_100us_Task: WdgMSupervisionReferenceCycle=1, WdgMExpectedAliveIndications=100, WdgMAliveSupervisionCheckpointRef=WdgMCore0ASILC_100usEndChkpnt
          WdgMAliveSupervision_Core0ASILC_10ms_Task: WdgMExpectedAliveIndications=10, WdgMSupervisionReferenceCycle=10, WdgMAliveSupervisionCheckpointRef=WdgMCore0ASILC_10msEndChkpnt
          WdgMAliveSupervision_Core0ASILC_1ms_Task: WdgMExpectedAliveIndications=10, WdgMSupervisionReferenceCycle=1, WdgMAliveSupervisionCheckpointRef=WdgMCore0ASILC_1msEndChkpnt
          WdgMAliveSupervision_Core0ASILC_40ms_Task: WdgMSupervisionReferenceCycle=12, WdgMExpectedAliveIndications=3, WdgMAliveSupervisionCheckpointRef=WdgMCore0ASILC_40msEndChkpnt
          WdgMAliveSupervision_Core0ASILC_5ms_Task: WdgMExpectedAliveIndications=10, WdgMSupervisionReferenceCycle=5, WdgMAliveSupervisionCheckpointRef=WdgMCore0ASILC_5msEndChkpnt
          WdgMAliveSupervision_Core1ASILA_100ms_Task: WdgMSupervisionReferenceCycle=20, WdgMExpectedAliveIndications=2, WdgMAliveSupervisionCheckpointRef=WdgMCore1ASILA_100msEndChkpnt
          WdgMAliveSupervision_Core1ASILA_100us_Task: WdgMExpectedAliveIndications=100, WdgMSupervisionReferenceCycle=1, WdgMAliveSupervisionCheckpointRef=WdgMCore1ASILA_100usEndChkpnt
          WdgMAliveSupervision_Core1ASILA_1ms_Task: WdgMSupervisionReferenceCycle=1, WdgMExpectedAliveIndications=10, WdgMAliveSupervisionCheckpointRef=WdgMCore1ASILA_1msEndChkpnt
          WdgMAliveSupervision_Core1ASILA_40ms_Task: WdgMSupervisionReferenceCycle=12, WdgMExpectedAliveIndications=3, WdgMAliveSupervisionCheckpointRef=WdgMCore1ASILA_40msEndChkpnt
          WdgMAliveSupervision_Core1ASILA_5ms_Task: WdgMExpectedAliveIndications=10, WdgMSupervisionReferenceCycle=5, WdgMAliveSupervisionCheckpointRef=WdgMCore1ASILA_5msEndChkpnt
        21 x WdgMLocalStatusParams:
          WdgMLocalStatusParams_Core0ASILA_100ms_Task: WdgMFailedAliveSupervisionRefCycleTol=0, WdgMLocalStatusSupervisedEntityRef=WdgMSupervisedEntity_06_Core0ASILA_100ms
          WdgMLocalStatusParams_Core0ASILA_10ms_Task: WdgMFailedAliveSupervisionRefCycleTol=0, WdgMLocalStatusSupervisedEntityRef=WdgMSupervisedEntity_08_Core0ASILA_10ms
          WdgMLocalStatusParams_Core0ASILA_1ms_Task: WdgMFailedAliveSupervisionRefCycleTol=1, WdgMLocalStatusSupervisedEntityRef=WdgMSupervisedEntity_10_Core0ASILA_1ms
          WdgMLocalStatusParams_Core0ASILA_40ms_Task: WdgMFailedAliveSupervisionRefCycleTol=0, WdgMLocalStatusSupervisedEntityRef=WdgMSupervisedEntity_07_Core0ASILA_40ms
          WdgMLocalStatusParams_Core0ASILA_5ms_Task: WdgMFailedAliveSupervisionRefCycleTol=0, WdgMLocalStatusSupervisedEntityRef=WdgMSupervisedEntity_09_Core0ASILA_5ms
          WdgMLocalStatusParams_Core0ASILB_100ms_Task: WdgMFailedAliveSupervisionRefCycleTol=0, WdgMLocalStatusSupervisedEntityRef=WdgMSupervisedEntity_11_Core0ASILB_100ms
          WdgMLocalStatusParams_Core0ASILB_10ms_Task: WdgMFailedAliveSupervisionRefCycleTol=0, WdgMLocalStatusSupervisedEntityRef=WdgMSupervisedEntity_13_Core0ASILB_10ms
          WdgMLocalStatusParams_Core0ASILB_1ms_Task: WdgMFailedAliveSupervisionRefCycleTol=1, WdgMLocalStatusSupervisedEntityRef=WdgMSupervisedEntity_15_Core0ASILB_1ms
          WdgMLocalStatusParams_Core0ASILB_40ms_Task: WdgMFailedAliveSupervisionRefCycleTol=0, WdgMLocalStatusSupervisedEntityRef=WdgMSupervisedEntity_12_Core0ASILB_40ms
          WdgMLocalStatusParams_Core0ASILB_5ms_Task: WdgMFailedAliveSupervisionRefCycleTol=0, WdgMLocalStatusSupervisedEntityRef=WdgMSupervisedEntity_14_Core0ASILB_5ms
          WdgMLocalStatusParams_Core0ASILC_100ms_Task: WdgMFailedAliveSupervisionRefCycleTol=0, WdgMLocalStatusSupervisedEntityRef=WdgMSupervisedEntity_00_Core0ASILC_100ms
          WdgMLocalStatusParams_Core0ASILC_100us_Task: WdgMFailedAliveSupervisionRefCycleTol=1, WdgMLocalStatusSupervisedEntityRef=WdgMSupervisedEntity_05_Core0ASILC_100us
          WdgMLocalStatusParams_Core0ASILC_10ms_Task: WdgMFailedAliveSupervisionRefCycleTol=0, WdgMLocalStatusSupervisedEntityRef=WdgMSupervisedEntity_02_Core0ASILC_10ms
          WdgMLocalStatusParams_Core0ASILC_1ms_Task: WdgMFailedAliveSupervisionRefCycleTol=1, WdgMLocalStatusSupervisedEntityRef=WdgMSupervisedEntity_04_Core0ASILC_1ms
          WdgMLocalStatusParams_Core0ASILC_40ms_Task: WdgMFailedAliveSupervisionRefCycleTol=0, WdgMLocalStatusSupervisedEntityRef=WdgMSupervisedEntity_01_Core0ASILC_40ms
          WdgMLocalStatusParams_Core0ASILC_5ms_Task: WdgMFailedAliveSupervisionRefCycleTol=0, WdgMLocalStatusSupervisedEntityRef=WdgMSupervisedEntity_03_Core0ASILC_5ms
          WdgMLocalStatusParams_Core1ASILA_100ms_Task: WdgMFailedAliveSupervisionRefCycleTol=0, WdgMLocalStatusSupervisedEntityRef=WdgMSupervisedEntity_17_Core1ASILA_100ms
          WdgMLocalStatusParams_Core1ASILA_100us_Task: WdgMFailedAliveSupervisionRefCycleTol=1, WdgMLocalStatusSupervisedEntityRef=WdgMSupervisedEntity_21_Core1ASILA_100us
          WdgMLocalStatusParams_Core1ASILA_1ms_Task: WdgMFailedAliveSupervisionRefCycleTol=1, WdgMLocalStatusSupervisedEntityRef=WdgMSupervisedEntity_20_Core1ASILA_1ms
          WdgMLocalStatusParams_Core1ASILA_40ms_Task: WdgMFailedAliveSupervisionRefCycleTol=0, WdgMLocalStatusSupervisedEntityRef=WdgMSupervisedEntity_18_Core1ASILA_40ms
          WdgMLocalStatusParams_Core1ASILA_5ms_Task: WdgMFailedAliveSupervisionRefCycleTol=0, WdgMLocalStatusSupervisedEntityRef=WdgMSupervisedEntity_19_Core1ASILA_5ms
        WdgMAliveSupervision_Core1ASILA_Sw100us_Task (WdgMAliveSupervision):
          WdgMSupervisionReferenceCycle = 1
          WdgMExpectedAliveIndications = 100
          WdgMMinMargin = 1
          WdgMMaxMargin = 1
          WdgMAliveSupervisionCheckpointRef = WdgMCore1ASILA_Sw100usEndChkpnt
        WdgMLocalStatusParams_Core1ASILA_Sw100us_Task (WdgMLocalStatusParams): WdgMFailedAliveSupervisionRefCycleTol=2, WdgMLocalStatusSupervisedEntityRef=WdgMSupervisedEntity_22_Core1ASILA_Sw100us
        WdgMLocalStatusParams_Core0ASILB_100us_Task (WdgMLocalStatusParams): WdgMFailedAliveSupervisionRefCycleTol=1, WdgMLocalStatusSupervisedEntityRef=WdgMSupervisedEntity_16_Core0ASILB_100us
        WdgMAliveSupervision_Core0ASILB_100us_Task (WdgMAliveSupervision):
          WdgMExpectedAliveIndications = 100
          WdgMMaxMargin = 1
          WdgMMinMargin = 1
          WdgMSupervisionReferenceCycle = 1
          WdgMAliveSupervisionCheckpointRef = WdgMCore0ASILB_100usEndChkpnt
      WdgMMode_1 (WdgMMode): WdgMExpiredSupervisionCycleTol=2, WdgMModeId=1, WdgMSupervisionCycle=0.01
        WdgMAliveSupervision_SE23_Core0_Alive_Mode1_1ms (WdgMAliveSupervision):
          WdgMExpectedAliveIndications = 10
          WdgMMaxMargin = 2
          WdgMMinMargin = 2
          WdgMSupervisionReferenceCycle = 1
          WdgMAliveSupervisionCheckpointRef = WdgMCheckpoint_Core0_Alive_Mode1_SE23_CP0_1ms
        WdgMAliveSupervision_SE24_Core1_Alive_Mode1_1ms (WdgMAliveSupervision):
          WdgMExpectedAliveIndications = 10
          WdgMMaxMargin = 2
          WdgMMinMargin = 2
          WdgMSupervisionReferenceCycle = 1
          WdgMAliveSupervisionCheckpointRef = WdgMCheckpoint_Core1_Alive_Mode1_SE24_CP0_1ms
        WdgMLocalStatusParams_SE23_Core0_Alive_Mode1_1ms (WdgMLocalStatusParams): WdgMFailedAliveSupervisionRefCycleTol=1, WdgMLocalStatusSupervisedEntityRef=WdgMSupervisedEntity_SE23_Core0_Alive_Mode1_1ms
        WdgMLocalStatusParams_SE24_Core1_Alive_Mode1_1ms (WdgMLocalStatusParams): WdgMFailedAliveSupervisionRefCycleTol=1, WdgMLocalStatusSupervisedEntityRef=WdgMSupervisedEntity_SE24_Core1_Alive_Mode1_1ms
        WdgMTrigger_0 (WdgMTrigger): WdgMTriggerConditionValue=500, WdgMWatchdogMode=WDGIF_SLOW_MODE, WdgMTriggerWatchdogRef=WdgMWatchdog_0
        WdgMDeadlineSupervision_SE25_Core0_Deadline_Mode1_CP0_CP1 (WdgMDeadlineSupervision):
          WdgMDeadlineMax = 0.022
          WdgMDeadlineMin = 0.018
          WdgMDeadlineStartRef = WdgMCheckpoint_Core0_Deadline_Mode1_SE25_CP0
          WdgMDeadlineStopRef = WdgMCheckpoint_Core0_Deadline_Mode1_SE25_CP1
        3 x WdgMLocalStatusParams, all with WdgMFailedAliveSupervisionRefCycleTol=1:
          WdgMLocalStatusParams_SE25_Core0_Deadline_Mode1: WdgMLocalStatusSupervisedEntityRef=WdgMSupervisedEntity_SE25_Core0_Deadline_Mode1
          WdgMLocalStatusParams_SE28_Core1_Logical_Mode1: WdgMLocalStatusSupervisedEntityRef=WdgMSupervisedEntity_SE28_Core1_Logical_Mode1
          WdgMLocalStatusParams_SE27_Core0_Logical_Mode1: WdgMLocalStatusSupervisedEntityRef=WdgMSupervisedEntity_SE27_Core0_Logical_Mode1
        WdgMExternalLogicalSupervision_Core0 (WdgMExternalLogicalSupervision):
          WdgMExternalCheckpointFinalRef = WdgMCheckpoint_Core0_Alive_Mode1_SE23_CP0_1ms
          WdgMExternalCheckpointInitialRef = WdgMCheckpoint_Core0_ExtLogical_Mode1_SE29_CP1
          WdgMExternalTransition_0 (WdgMExternalTransition):
            WdgMExternalTransitionDestRef = WdgMCheckpoint_Core0_ExtLogical_Alive_Mode1_SE29_CP0
            WdgMExternalTransitionSourceRef = WdgMCheckpoint_Core0_ExtLogical_Mode1_SE29_CP1
          WdgMExternalTransition_1 (WdgMExternalTransition):
            WdgMExternalTransitionDestRef = WdgMCheckpoint_Core0_Alive_Mode1_SE23_CP0_1ms
            WdgMExternalTransitionSourceRef = WdgMCheckpoint_Core0_ExtLogical_Alive_Mode1_SE29_CP0
        WdgMLocalStatusParams_SE29_Core0_ExtLogical_Mode1 (WdgMLocalStatusParams): WdgMFailedAliveSupervisionRefCycleTol=1, WdgMLocalStatusSupervisedEntityRef=WdgMSupervisedEntity_SE29_Core0_ExtLogical_Mode1
        WdgMDeadlineSupervision_SE26_Core1_Deadline_Mode1_CP0_CP1 (WdgMDeadlineSupervision):
          WdgMDeadlineMax = 0.022
          WdgMDeadlineMin = 0.018
          WdgMDeadlineStartRef = WdgMCheckpoint_Core1_Deadline_Mode1_SE26_CP0
          WdgMDeadlineStopRef = WdgMCheckpoint_Core1_Deadline_Mode1_SE26_CP1
        WdgMLocalStatusParams_SE26_Core1_Deadline_Mode1 (WdgMLocalStatusParams): WdgMFailedAliveSupervisionRefCycleTol=1, WdgMLocalStatusSupervisedEntityRef=WdgMSupervisedEntity_SE26_Core1_Deadline_Mode1
        WdgMLocalStatusParams_SE30_Core1_ExtLogical_Mode1 (WdgMLocalStatusParams): WdgMFailedAliveSupervisionRefCycleTol=1, WdgMLocalStatusSupervisedEntityRef=WdgMSupervisedEntity_SE30_Core1_ExtLogical_Mode1
        WdgMExternalLogicalSupervision_Core1 (WdgMExternalLogicalSupervision):
          WdgMExternalCheckpointFinalRef = WdgMCheckpoint_Core1_ExtLogical_Mode1_SE30_CP1
          WdgMExternalCheckpointInitialRef = WdgMCheckpoint_Core1_ExtLogical_Mode1_SE24_CP1
          WdgMExternalTransition_0 (WdgMExternalTransition):
            WdgMExternalTransitionDestRef = WdgMCheckpoint_Core1_ExtLogical_Mode1_SE30_CP0
            WdgMExternalTransitionSourceRef = WdgMCheckpoint_Core1_ExtLogical_Mode1_SE24_CP1
          WdgMExternalTransition_1 (WdgMExternalTransition):
            WdgMExternalTransitionDestRef = WdgMCheckpoint_Core1_ExtLogical_Mode1_SE30_CP1
            WdgMExternalTransitionSourceRef = WdgMCheckpoint_Core1_ExtLogical_Mode1_SE30_CP0
        3 x WdgMLocalStatusParams, all with WdgMFailedAliveSupervisionRefCycleTol=1:
          WdgMLocalStatusParams_SE31_Core0_Alive_Mode1_5ms: WdgMLocalStatusSupervisedEntityRef=WdgMSupervisedEntity_SE31_Core0_Alive_Mode1_5ms
          WdgMLocalStatusParams_SE32_Core0_Alive_Mode1_10ms: WdgMLocalStatusSupervisedEntityRef=WdgMSupervisedEntity_SE32_Core0_Alive_Mode1_10ms
          WdgMLocalStatusParams_SE33_Core0_Alive_Mode1_100ms: WdgMLocalStatusSupervisedEntityRef=WdgMSupervisedEntity_SE33_Core0_Alive_Mode1_100ms
        3 x WdgMAliveSupervision:
          WdgMAliveSupervision_SE31_Core0_Alive_Mode1_5ms: WdgMExpectedAliveIndications=10, WdgMMaxMargin=12, WdgMMinMargin=8, WdgMSupervisionReferenceCycle=5, WdgMAliveSupervisionCheckpointRef=WdgMCheckpoint_Core0_Alive_Mode1_SE31_CP0_5ms
          WdgMAliveSupervision_SE32_Core0_Alive_Mode1_10ms: WdgMExpectedAliveIndications=10, WdgMMaxMargin=12, WdgMMinMargin=8, WdgMSupervisionReferenceCycle=10, WdgMAliveSupervisionCheckpointRef=WdgMCheckpoint_Core0_Alive_Mode1_SE32_CP0_10ms
          WdgMAliveSupervision_SE33_Core0_Alive_Mode1_100ms: WdgMExpectedAliveIndications=1, WdgMMaxMargin=1, WdgMMinMargin=1, WdgMSupervisionReferenceCycle=10, WdgMAliveSupervisionCheckpointRef=WdgMCheckpoint_Core0_Alive_Mode1_SE33_CP0_100ms
        WdgMLocalStatusParams_SE34_Core1_Alive_Mode1_10ms (WdgMLocalStatusParams): WdgMFailedAliveSupervisionRefCycleTol=1, WdgMLocalStatusSupervisedEntityRef=WdgMSupervisedEntity_SE34_Core1_Alive_Mode1_10ms
        WdgMLocalStatusParams_SE35_Core1_Alive_Mode1_100ms (WdgMLocalStatusParams): WdgMFailedAliveSupervisionRefCycleTol=1, WdgMLocalStatusSupervisedEntityRef=WdgMSupervisedEntity_SE35_Core1_Alive_Mode1_100ms
        WdgMAliveSupervision_SE34_Core1_Alive_Mode1_10ms (WdgMAliveSupervision):
          WdgMExpectedAliveIndications = 10
          WdgMMaxMargin = 12
          WdgMMinMargin = 8
          WdgMSupervisionReferenceCycle = 10
          WdgMAliveSupervisionCheckpointRef = WdgMCheckpoint_Core1_Alive_Mode1_SE34_10ms
        WdgMAliveSupervision_SE35_Core1_Alive_Mode1_100ms (WdgMAliveSupervision):
          WdgMExpectedAliveIndications = 1
          WdgMMaxMargin = 1
          WdgMMinMargin = 1
          WdgMSupervisionReferenceCycle = 10
          WdgMAliveSupervisionCheckpointRef = WdgMCheckpoint_Core1_Alive_Mode1_SE35_100ms
        WdgMLocalStatusParams_SE36_Core0_Part1_Alive_Mode1_1ms (WdgMLocalStatusParams): WdgMFailedAliveSupervisionRefCycleTol=1, WdgMLocalStatusSupervisedEntityRef=WdgMSupervisedEntity_SE36_Core0_Part1_Alive_Mode1_1ms
        WdgMAliveSupervision_SE36_Core0_Part1_Alive_Mode1_1ms (WdgMAliveSupervision):
          WdgMExpectedAliveIndications = 10
          WdgMMaxMargin = 12
          WdgMMinMargin = 8
          WdgMSupervisionReferenceCycle = 1
          WdgMAliveSupervisionCheckpointRef = WdgMCheckpoint_Core0_Part1_Alive_Mode1_SE36_CP0_1ms
        3 x WdgMLocalStatusParams, all with WdgMFailedAliveSupervisionRefCycleTol=1:
          WdgMLocalStatusParams_SE37_Core0_Part1_Deadline_Mode1: WdgMLocalStatusSupervisedEntityRef=WdgMSupervisedEntity_SE37_Core0_Part1_Deadline_Mode1
          WdgMLocalStatusParams_SE38_Core0_Part1_Logical_Mode1: WdgMLocalStatusSupervisedEntityRef=WdgMSupervisedEntity_SE38_Core0_Part1_Logical_Mode1
          WdgMLocalStatusParams_SE39_Core0_Part1_ExtLogical_Mode1: WdgMLocalStatusSupervisedEntityRef=WdgMSupervisedEntity_SE39_Core0_Part1_ExtLogical_Mode1
        WdgMDeadlineSupervision_SE37_Core0_Part1_Deadline_Mode1_CP0_CP1 (WdgMDeadlineSupervision):
          WdgMDeadlineMax = 0.022
          WdgMDeadlineMin = 0.018
          WdgMDeadlineStartRef = WdgMCheckpoint_Core0_Part1_Deadline_Mode1_SE37_CP0
          WdgMDeadlineStopRef = WdgMCheckpoint_Core0_Part1_Deadline_Mode1_SE37_CP1
        WdgMExternalLogicalSupervision_Core0_Part1 (WdgMExternalLogicalSupervision):
          WdgMExternalCheckpointFinalRef = WdgMCheckpoint_Core0_Part1_ExtLogical_Mode1_SE36_CP1
          WdgMExternalCheckpointInitialRef = WdgMCheckpoint_Core0_Part1_ExtLogical_Mode1_SE39_CP0
          WdgMExternalTransition_0 (WdgMExternalTransition):
            WdgMExternalTransitionDestRef = WdgMCheckpoint_Core0_Part1_ExtLogical_Mode1_SE39_CP1
            WdgMExternalTransitionSourceRef = WdgMCheckpoint_Core0_Part1_ExtLogical_Mode1_SE39_CP0
          WdgMExternalTransition_1 (WdgMExternalTransition):
            WdgMExternalTransitionDestRef = WdgMCheckpoint_Core0_Part1_ExtLogical_Mode1_SE36_CP1
            WdgMExternalTransitionSourceRef = WdgMCheckpoint_Core0_Part1_ExtLogical_Mode1_SE39_CP1
        WdgMLocalStatusParams_SE40_Core0_Part2_Alive_Mode1_1ms (WdgMLocalStatusParams): WdgMFailedAliveSupervisionRefCycleTol=1, WdgMLocalStatusSupervisedEntityRef=WdgMSupervisedEntity_SE40_Core0_Part2_Alive_Mode1_1ms
        WdgMAliveSupervision_SE40_Core0_Part2_Alive_Mode1_1ms (WdgMAliveSupervision):
          WdgMMinMargin = 8
          WdgMMaxMargin = 12
          WdgMExpectedAliveIndications = 10
          WdgMSupervisionReferenceCycle = 1
          WdgMAliveSupervisionCheckpointRef = WdgMCheckpoint_Core0_Part2_Alive_Mode1_SE40_CP0_1ms
    WdgMGeneral_0 (WdgMGeneral): WdgMVersionInfoApi=true, WdgMOffModeEnabled=true, WdgMImmediateReset=false, WdgMDevErrorDetect=true, WdgMDemStoppedSupervisionReport=true
      WdgMWatchdog_0 (WdgMWatchdog): WdgMWatchdogName=Watchdog0, WdgMWatchdogDeviceRef=(unset)
      20 x WdgMSupervisedEntity:
        WdgMSupervisedEntity_06_Core0ASILA_100ms: WdgMSupervisedEntityId=6, WdgMSEPartitionRef=WdgM_Partition1, WdgMEcucPartitionRef=(unset)
          WdgMCore0ASILA_100msEndChkpnt (WdgMCheckpoint): WdgMCheckpointId=0
        WdgMSupervisedEntity_08_Core0ASILA_10ms: WdgMSupervisedEntityId=8, WdgMSEPartitionRef=WdgM_Partition1, WdgMEcucPartitionRef=(unset)
          WdgMCore0ASILA_10msEndChkpnt (WdgMCheckpoint): WdgMCheckpointId=0
        WdgMSupervisedEntity_10_Core0ASILA_1ms: WdgMSupervisedEntityId=10, WdgMSEPartitionRef=WdgM_Partition1, WdgMEcucPartitionRef=(unset)
          WdgMCore0ASILA_1msEndChkpnt (WdgMCheckpoint): WdgMCheckpointId=0
        WdgMSupervisedEntity_07_Core0ASILA_40ms: WdgMSupervisedEntityId=7, WdgMEcucPartitionRef=(unset), WdgMSEPartitionRef=WdgM_Partition1
          WdgMCore0ASILA_40msEndChkpnt (WdgMCheckpoint): WdgMCheckpointId=0
        WdgMSupervisedEntity_09_Core0ASILA_5ms: WdgMSupervisedEntityId=9, WdgMEcucPartitionRef=(unset), WdgMSEPartitionRef=WdgM_Partition1
          WdgMCore0ASILA_5msEndChkpnt (WdgMCheckpoint): WdgMCheckpointId=0
        WdgMSupervisedEntity_11_Core0ASILB_100ms: WdgMSupervisedEntityId=11, WdgMEcucPartitionRef=Partition0, WdgMSEPartitionRef=WdgM_Partition2
          WdgMCore0ASILB_100msEndChkpnt (WdgMCheckpoint): WdgMCheckpointId=0
        WdgMSupervisedEntity_13_Core0ASILB_10ms: WdgMSupervisedEntityId=13, WdgMSEPartitionRef=WdgM_Partition2, WdgMEcucPartitionRef=Partition0
          WdgMCore0ASILB_10msEndChkpnt (WdgMCheckpoint): WdgMCheckpointId=0
        WdgMSupervisedEntity_15_Core0ASILB_1ms: WdgMSupervisedEntityId=15, WdgMEcucPartitionRef=Partition0, WdgMSEPartitionRef=WdgM_Partition2
          WdgMCore0ASILB_1msEndChkpnt (WdgMCheckpoint): WdgMCheckpointId=0
        WdgMSupervisedEntity_12_Core0ASILB_40ms: WdgMSupervisedEntityId=12, WdgMEcucPartitionRef=Partition0, WdgMSEPartitionRef=WdgM_Partition2
          WdgMCore0ASILB_40msEndChkpnt (WdgMCheckpoint): WdgMCheckpointId=0
        WdgMSupervisedEntity_14_Core0ASILB_5ms: WdgMSupervisedEntityId=14, WdgMEcucPartitionRef=Partition0, WdgMSEPartitionRef=WdgM_Partition2
          WdgMCore0ASILB_5msEndChkpnt (WdgMCheckpoint): WdgMCheckpointId=0
        WdgMSupervisedEntity_00_Core0ASILC_100ms: WdgMSupervisedEntityId=0, WdgMSEPartitionRef=WdgM, WdgMEcucPartitionRef=Partition1
          WdgMCore0ASILC_100msEndChkpnt (WdgMCheckpoint): WdgMCheckpointId=0
        WdgMSupervisedEntity_05_Core0ASILC_100us: WdgMSupervisedEntityId=5, WdgMSEPartitionRef=WdgM, WdgMEcucPartitionRef=Partition1
          WdgMCore0ASILC_100usEndChkpnt (WdgMCheckpoint): WdgMCheckpointId=0
        WdgMSupervisedEntity_02_Core0ASILC_10ms: WdgMSupervisedEntityId=2, WdgMSEPartitionRef=WdgM, WdgMEcucPartitionRef=Partition1
          WdgMCore0ASILC_10msEndChkpnt (WdgMCheckpoint): WdgMCheckpointId=0
        WdgMSupervisedEntity_04_Core0ASILC_1ms: WdgMSupervisedEntityId=4, WdgMEcucPartitionRef=Partition1, WdgMSEPartitionRef=WdgM
          WdgMCore0ASILC_1msEndChkpnt (WdgMCheckpoint): WdgMCheckpointId=0
        WdgMSupervisedEntity_01_Core0ASILC_40ms: WdgMSupervisedEntityId=1, WdgMSEPartitionRef=WdgM, WdgMEcucPartitionRef=Partition1
          WdgMCore0ASILC_40msEndChkpnt (WdgMCheckpoint): WdgMCheckpointId=0
        WdgMSupervisedEntity_17_Core1ASILA_100ms: WdgMSupervisedEntityId=17, WdgMEcucPartitionRef=Partition3, WdgMSEPartitionRef=WdgM_Partition3
          WdgMCore1ASILA_100msEndChkpnt (WdgMCheckpoint): WdgMCheckpointId=0
        WdgMSupervisedEntity_21_Core1ASILA_100us: WdgMSupervisedEntityId=21, WdgMSEPartitionRef=WdgM_Partition3, WdgMEcucPartitionRef=Partition3
          WdgMCore1ASILA_100usEndChkpnt (WdgMCheckpoint): WdgMCheckpointId=0
        WdgMSupervisedEntity_20_Core1ASILA_1ms: WdgMSupervisedEntityId=20, WdgMSEPartitionRef=WdgM_Partition3, WdgMEcucPartitionRef=Partition3
          WdgMCore1ASILA_1msEndChkpnt (WdgMCheckpoint): WdgMCheckpointId=0
        WdgMSupervisedEntity_18_Core1ASILA_40ms: WdgMSupervisedEntityId=18, WdgMEcucPartitionRef=Partition3, WdgMSEPartitionRef=WdgM_Partition3
          WdgMCore1ASILA_40msEndChkpnt (WdgMCheckpoint): WdgMCheckpointId=0
        WdgMSupervisedEntity_19_Core1ASILA_5ms: WdgMSupervisedEntityId=19, WdgMSEPartitionRef=WdgM_Partition3, WdgMEcucPartitionRef=Partition3
          WdgMCore1ASILA_5msEndChkpnt (WdgMCheckpoint): WdgMCheckpointId=0
      4 x WdgM_Partition:
        WdgM_Partition1: WdgMMasterPartition=false, WdgMPartitionRef=(unset), WdgMCoreRef=EcucCoreDefinition_0
        WdgM_Partition2: WdgMMasterPartition=false, WdgMPartitionRef=Partition0, WdgMCoreRef=EcucCoreDefinition_0
        WdgM: WdgMMasterPartition=true, WdgMPartitionRef=Partition1, WdgMCoreRef=EcucCoreDefinition_0
        WdgM_Partition3: WdgMMasterPartition=false, WdgMSATAliveTimeOut=0.010, WdgMSATAliveTimeOutNotf=WdgMSATAliveTimeoutFunc, WdgMCoreRef=(unset), WdgMPartitionRef=Partition3
      21 x WdgMSupervisedEntity:
        WdgMSupervisedEntity_22_Core1ASILA_Sw100us: WdgMSupervisedEntityId=22, WdgMEcucPartitionRef=Partition3, WdgMSEPartitionRef=WdgM_Partition3
          WdgMCore1ASILA_Sw100usEndChkpnt (WdgMCheckpoint): WdgMCheckpointId=0
        WdgMSupervisedEntity_03_Core0ASILC_5ms: WdgMSupervisedEntityId=3, WdgMEcucPartitionRef=Partition1, WdgMSEPartitionRef=WdgM
          WdgMCore0ASILC_5msEndChkpnt (WdgMCheckpoint): WdgMCheckpointId=0
        WdgMSupervisedEntity_16_Core0ASILB_100us: WdgMSupervisedEntityId=16, WdgMEcucPartitionRef=Partition0, WdgMSEPartitionRef=WdgM_Partition2
          WdgMCore0ASILB_100usEndChkpnt (WdgMCheckpoint): WdgMCheckpointId=0
        WdgMSupervisedEntity_SE31_Core0_Alive_Mode1_5ms: WdgMSupervisedEntityId=31, WdgMSEPartitionRef=WdgM
          WdgMCheckpoint_Core0_Alive_Mode1_SE31_CP0_5ms (WdgMCheckpoint): WdgMCheckpointId=0
        WdgMSupervisedEntity_SE32_Core0_Alive_Mode1_10ms: WdgMSupervisedEntityId=32, WdgMSEPartitionRef=WdgM
          WdgMCheckpoint_Core0_Alive_Mode1_SE32_CP0_10ms (WdgMCheckpoint): WdgMCheckpointId=0
        WdgMSupervisedEntity_SE33_Core0_Alive_Mode1_100ms: WdgMSupervisedEntityId=33, WdgMSEPartitionRef=WdgM
          WdgMCheckpoint_Core0_Alive_Mode1_SE33_CP0_100ms (WdgMCheckpoint): WdgMCheckpointId=0
        WdgMSupervisedEntity_SE23_Core0_Alive_Mode1_1ms: WdgMSupervisedEntityId=23, WdgMSEPartitionRef=WdgM
          WdgMCheckpoint_Core0_Alive_Mode1_SE23_CP0_1ms (WdgMCheckpoint): WdgMCheckpointId=0
        WdgMSupervisedEntity_SE25_Core0_Deadline_Mode1: WdgMSupervisedEntityId=25, WdgMOSCounter=(unset), WdgMSEPartitionRef=WdgM
          WdgMCheckpoint_Core0_Deadline_Mode1_SE25_CP0 (WdgMCheckpoint): WdgMCheckpointId=0
          WdgMCheckpoint_Core0_Deadline_Mode1_SE25_CP1 (WdgMCheckpoint): WdgMCheckpointId=1
        WdgMSupervisedEntity_SE29_Core0_ExtLogical_Mode1: WdgMSupervisedEntityId=29, WdgMSEPartitionRef=WdgM
          WdgMCheckpoint_Core0_ExtLogical_Alive_Mode1_SE29_CP0 (WdgMCheckpoint): WdgMCheckpointId=0
          WdgMCheckpoint_Core0_ExtLogical_Mode1_SE29_CP1 (WdgMCheckpoint): WdgMCheckpointId=1
        WdgMSupervisedEntity_SE27_Core0_Logical_Mode1: WdgMSupervisedEntityId=27, WdgMInternalCheckpointInitialRef=WdgMCheckpoint_Core0_Logical_Mode1_SE27_CP0, WdgMInternallCheckpointFinalRef=WdgMCheckpoint_Core0_Logical_Mode1_SE27_CP2, WdgMSEPartitionRef=WdgM
          3 x WdgMCheckpoint:
            WdgMCheckpoint_Core0_Logical_Mode1_SE27_CP{0..2}: WdgMCheckpointId={0..2}
          WdgMInternalTransition_0 (WdgMInternalTransition):
            WdgMInternalTransitionDestRef = WdgMCheckpoint_Core0_Logical_Mode1_SE27_CP1
            WdgMInternalTransitionSourceRef = WdgMCheckpoint_Core0_Logical_Mode1_SE27_CP0
          WdgMInternalTransition_1 (WdgMInternalTransition):
            WdgMInternalTransitionDestRef = WdgMCheckpoint_Core0_Logical_Mode1_SE27_CP2
            WdgMInternalTransitionSourceRef = WdgMCheckpoint_Core0_Logical_Mode1_SE27_CP1
        WdgMSupervisedEntity_SE36_Core0_Part1_Alive_Mode1_1ms: WdgMSupervisedEntityId=36, WdgMSEPartitionRef=WdgM_Partition1
          WdgMCheckpoint_Core0_Part1_Alive_Mode1_SE36_CP0_1ms (WdgMCheckpoint): WdgMCheckpointId=0
          WdgMCheckpoint_Core0_Part1_ExtLogical_Mode1_SE36_CP1 (WdgMCheckpoint): WdgMCheckpointId=1
        WdgMSupervisedEntity_SE37_Core0_Part1_Deadline_Mode1: WdgMSupervisedEntityId=37, WdgMSEPartitionRef=WdgM_Partition1, WdgMOSCounter=(unset)
          WdgMCheckpoint_Core0_Part1_Deadline_Mode1_SE37_CP0 (WdgMCheckpoint): WdgMCheckpointId=0
          WdgMCheckpoint_Core0_Part1_Deadline_Mode1_SE37_CP1 (WdgMCheckpoint): WdgMCheckpointId=1
        WdgMSupervisedEntity_SE39_Core0_Part1_ExtLogical_Mode1: WdgMSupervisedEntityId=39, WdgMSEPartitionRef=WdgM_Partition1
          WdgMCheckpoint_Core0_Part1_ExtLogical_Mode1_SE39_CP0 (WdgMCheckpoint): WdgMCheckpointId=0
          WdgMCheckpoint_Core0_Part1_ExtLogical_Mode1_SE39_CP1 (WdgMCheckpoint): WdgMCheckpointId=1
        WdgMSupervisedEntity_SE38_Core0_Part1_Logical_Mode1: WdgMSupervisedEntityId=38, WdgMSEPartitionRef=WdgM_Partition1, WdgMInternalCheckpointInitialRef=WdgMCheckpoint_Core0_Part1_Logical_Mode1_SE38_CP0, WdgMInternallCheckpointFinalRef=WdgMCheckpoint_Core0_Part1_Logical_Mode1_SE38_CP2
          3 x WdgMCheckpoint:
            WdgMCheckpoint_Core0_Part1_Logical_Mode1_SE38_CP{0..2}: WdgMCheckpointId={0..2}
          WdgMInternalTransition_0 (WdgMInternalTransition):
            WdgMInternalTransitionDestRef = WdgMCheckpoint_Core0_Part1_Logical_Mode1_SE38_CP1
            WdgMInternalTransitionSourceRef = WdgMCheckpoint_Core0_Part1_Logical_Mode1_SE38_CP0
          WdgMInternalTransition_1 (WdgMInternalTransition):
            WdgMInternalTransitionDestRef = WdgMCheckpoint_Core0_Part1_Logical_Mode1_SE38_CP2
            WdgMInternalTransitionSourceRef = WdgMCheckpoint_Core0_Part1_Logical_Mode1_SE38_CP1
        WdgMSupervisedEntity_SE40_Core0_Part2_Alive_Mode1_1ms: WdgMSupervisedEntityId=40, WdgMSEPartitionRef=WdgM_Partition2
          WdgMCheckpoint_Core0_Part2_Alive_Mode1_SE40_CP0_1ms (WdgMCheckpoint): WdgMCheckpointId=0
        WdgMSupervisedEntity_SE34_Core1_Alive_Mode1_10ms: WdgMSupervisedEntityId=34, WdgMSEPartitionRef=WdgM_Partition3
          WdgMCheckpoint_Core1_Alive_Mode1_SE34_10ms (WdgMCheckpoint): WdgMCheckpointId=0
        WdgMSupervisedEntity_SE35_Core1_Alive_Mode1_100ms: WdgMSupervisedEntityId=35, WdgMSEPartitionRef=WdgM_Partition3
          WdgMCheckpoint_Core1_Alive_Mode1_SE35_100ms (WdgMCheckpoint): WdgMCheckpointId=0
        WdgMSupervisedEntity_SE24_Core1_Alive_Mode1_1ms: WdgMSupervisedEntityId=24, WdgMSEPartitionRef=WdgM_Partition3
          WdgMCheckpoint_Core1_Alive_Mode1_SE24_CP0_1ms (WdgMCheckpoint): WdgMCheckpointId=0
          WdgMCheckpoint_Core1_ExtLogical_Mode1_SE24_CP1 (WdgMCheckpoint): WdgMCheckpointId=1
        WdgMSupervisedEntity_SE26_Core1_Deadline_Mode1: WdgMSupervisedEntityId=26, WdgMOSCounter=(unset), WdgMSEPartitionRef=WdgM_Partition3
          WdgMCheckpoint_Core1_Deadline_Mode1_SE26_CP0 (WdgMCheckpoint): WdgMCheckpointId=0
          WdgMCheckpoint_Core1_Deadline_Mode1_SE26_CP1 (WdgMCheckpoint): WdgMCheckpointId=1
        WdgMSupervisedEntity_SE30_Core1_ExtLogical_Mode1: WdgMSupervisedEntityId=30, WdgMSEPartitionRef=WdgM_Partition3
          WdgMCheckpoint_Core1_ExtLogical_Mode1_SE30_CP0 (WdgMCheckpoint): WdgMCheckpointId=0
          WdgMCheckpoint_Core1_ExtLogical_Mode1_SE30_CP1 (WdgMCheckpoint): WdgMCheckpointId=1
        WdgMSupervisedEntity_SE28_Core1_Logical_Mode1: WdgMSupervisedEntityId=28, WdgMInternalCheckpointInitialRef=WdgMCheckpoint_Core1_Logical_Mode1_SE28_CP0, WdgMInternallCheckpointFinalRef=WdgMCheckpoint_Core1_Logical_Mode1_SE28_CP2, WdgMSEPartitionRef=WdgM_Partition3
          3 x WdgMCheckpoint:
            WdgMCheckpoint_Core1_Logical_Mode1_SE28_CP{0..2}: WdgMCheckpointId={0..2}
          WdgMInternalTransition_0 (WdgMInternalTransition):
            WdgMInternalTransitionDestRef = WdgMCheckpoint_Core1_Logical_Mode1_SE28_CP1
            WdgMInternalTransitionSourceRef = WdgMCheckpoint_Core1_Logical_Mode1_SE28_CP0
          WdgMInternalTransition_1 (WdgMInternalTransition):
            WdgMInternalTransitionDestRef = WdgMCheckpoint_Core1_Logical_Mode1_SE28_CP2
            WdgMInternalTransitionSourceRef = WdgMCheckpoint_Core1_Logical_Mode1_SE28_CP1
